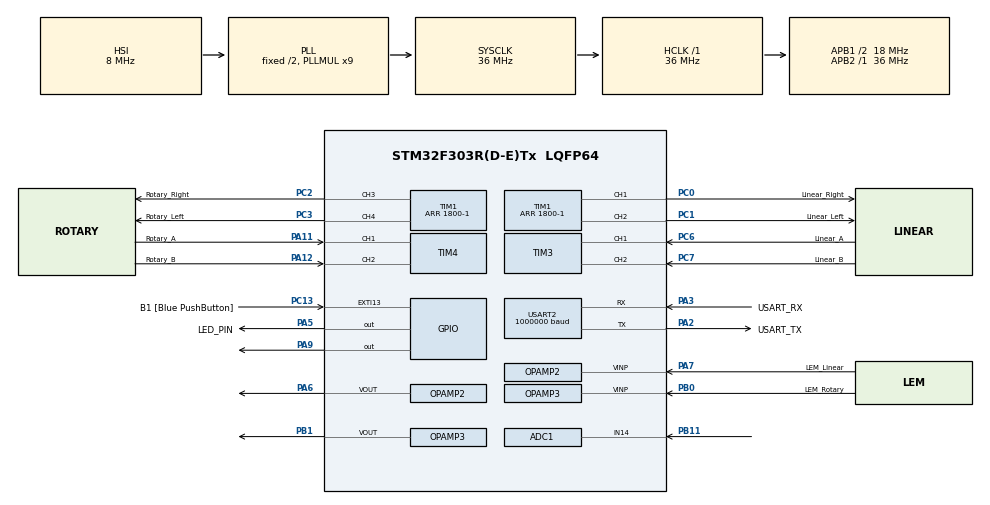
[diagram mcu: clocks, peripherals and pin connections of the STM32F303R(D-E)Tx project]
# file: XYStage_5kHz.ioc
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ADC1.Channel-6\#ChannelRegularConversion=ADC_CHANNEL_14
ADC1.ContinuousConvMode=ENABLE
ADC1.NbrOfConversionFlag=1
ADC1.Offset-6\#ChannelRegularConversion=0
ADC1.OffsetNumber-6\#ChannelRegularConversion=ADC_OFFSET_NONE
ADC1.Rank-6\#ChannelRegularConversion=1
ADC1.SamplingTime-6\#ChannelRegularConversion=ADC_SAMPLETIME_1CYCLE_5
ADC1.master=1
ADC2.Channel-0\#ChannelRegularConversion=ADC_CHANNEL_3
ADC2.ContinuousConvMode=DISABLE
ADC2.ExternalTrigConv=ADC_EXTERNALTRIGCONV_T1_TRGO
ADC2.NbrOfConversionFlag=1
ADC2.Offset-0\#ChannelRegularConversion=0
ADC2.OffsetNumber-0\#ChannelRegularConversion=ADC_OFFSET_NONE
ADC2.Rank-0\#ChannelRegularConversion=1
ADC2.SamplingTime-0\#ChannelRegularConversion=ADC_SAMPLETIME_61CYCLES_5
ADC2.SamplingTimeOPAMP-0\#ChannelRegularConversion=ADC_SAMPLETIME_61CYCLES_5
ADC3.Channel-0\#ChannelRegularConversion=ADC_CHANNEL_1
ADC3.ContinuousConvMode=DISABLE
ADC3.ExternalTrigConv=ADC_EXTERNALTRIGCONV_T1_TRGO
ADC3.NbrOfConversion=1
ADC3.NbrOfConversionFlag=1
ADC3.Offset-0\#ChannelRegularConversion=0
ADC3.OffsetNumber-0\#ChannelRegularConversion=ADC_OFFSET_NONE
ADC3.Rank-0\#ChannelRegularConversion=1
ADC3.SamplingTime-0\#ChannelRegularConversion=ADC_SAMPLETIME_19CYCLES_5
ADC3.master=1
Dma.Request0=USART2_RX
Dma.Request1=USART2_TX
Dma.USART2_RX.0.Direction=DMA_PERIPH_TO_MEMORY
Dma.USART2_RX.0.Instance=DMA1_Channel6
Dma.USART2_RX.0.MemDataAlignment=DMA_MDATAALIGN_BYTE
Dma.USART2_RX.0.MemInc=DMA_MINC_ENABLE
Dma.USART2_RX.0.Mode=DMA_NORMAL
Dma.USART2_RX.0.PeriphDataAlignment=DMA_PDATAALIGN_BYTE
Dma.USART2_RX.0.PeriphInc=DMA_PINC_DISABLE
Dma.USART2_RX.0.Priority=DMA_PRIORITY_VERY_HIGH
Dma.USART2_TX.1.Direction=DMA_MEMORY_TO_PERIPH
Dma.USART2_TX.1.Instance=DMA1_Channel7
Dma.USART2_TX.1.MemDataAlignment=DMA_MDATAALIGN_BYTE
Dma.USART2_TX.1.MemInc=DMA_MINC_ENABLE
Dma.USART2_TX.1.Mode=DMA_NORMAL
Dma.USART2_TX.1.PeriphDataAlignment=DMA_PDATAALIGN_BYTE
Dma.USART2_TX.1.PeriphInc=DMA_PINC_DISABLE
Dma.USART2_TX.1.Priority=DMA_PRIORITY_VERY_HIGH
Mcu.Family=STM32F3
Mcu.Name=STM32F303R(D-E)Tx
Mcu.Package=LQFP64
NVIC.ADC3_IRQn=true\:0\:0\:false\:false\:true\:true\:true\:true
NVIC.DMA1_Channel6_IRQn=true\:0\:0\:false\:false\:true\:false\:true\:true
NVIC.DMA1_Channel7_IRQn=true\:0\:0\:false\:false\:true\:false\:true\:true
NVIC.PriorityGroup=NVIC_PRIORITYGROUP_0
NVIC.USART2_IRQn=true\:0\:0\:false\:false\:true\:true\:true\:true
PA11.GPIO_Label=Rotary_A
PA11.Signal=S_TIM4_CH1
PA12.GPIO_Label=Rotary_B
PA12.Signal=S_TIM4_CH2
PA13.GPIO_Label=TMS
PA13.Mode=Serial_Wire
PA13.Signal=SYS_JTMS-SWDIO
PA14.GPIO_Label=TCK
PA14.Mode=Serial_Wire
PA14.Signal=SYS_JTCK-SWCLK
PA2.GPIO_Label=USART_TX
PA2.GPIO_Mode=GPIO_MODE_AF_PP
PA2.GPIO_PuPd=GPIO_NOPULL
PA2.GPIO_Speed=GPIO_SPEED_FREQ_LOW
PA2.Mode=Asynchronous
PA2.Signal=USART2_TX
PA3.GPIO_Label=USART_RX
PA3.GPIO_Mode=GPIO_MODE_AF_PP
PA3.GPIO_PuPd=GPIO_NOPULL
PA3.GPIO_Speed=GPIO_SPEED_FREQ_LOW
PA3.Mode=Asynchronous
PA3.Signal=USART2_RX
PA5.GPIO_Label=LED_PIN
PA5.Signal=GPIO_Output
PA6.Signal=SharedAnalog_PA6
PA7.GPIO_Label=LEM_Linear
PA7.Mode=Follower
PA7.Signal=OPAMP2_VINP
PA9.Signal=GPIO_Output
PB0.GPIO_Label=LEM_Rotary
PB0.Mode=Follower
PB0.Signal=OPAMP3_VINP
PB1.Signal=SharedAnalog_PB1
PB11.Mode=IN14-Single-Ended
PB11.Signal=ADC1_IN14
PB3.GPIO_Label=SWO
PB3.Signal=SYS_JTDO-TRACESWO
PC0.GPIO_Label=Linear_Right
PC0.Signal=S_TIM1_CH1
PC1.GPIO_Label=Linear_Left
PC1.Signal=S_TIM1_CH2
PC12.Signal=UART5_TX
PC13.GPIO_Label=B1 [Blue PushButton]
PC13.GPIO_ModeDefaultEXTI=GPIO_MODE_IT_FALLING
PC13.Signal=GPXTI13
PC14-OSC32_IN.Mode=LSE-External-Oscillator
PC14-OSC32_IN.Signal=RCC_OSC32_IN
PC15-OSC32_OUT.Mode=LSE-External-Oscillator
PC15-OSC32_OUT.Signal=RCC_OSC32_OUT
PC2.GPIO_Label=Rotary_Right
PC2.Signal=S_TIM1_CH3
PC3.GPIO_Label=Rotary_Left
PC3.Signal=S_TIM1_CH4
PC6.GPIO_Label=Linear_A
PC6.Signal=S_TIM3_CH1
PC7.GPIO_Label=Linear_B
PC7.Signal=S_TIM3_CH2
PD2.Signal=UART5_RX
PF0-OSC_IN.Mode=HSE-External-Clock-Source
PF0-OSC_IN.Signal=RCC_OSC_IN
PF1-OSC_OUT.Signal=RCC_OSC_OUT
ProjectManager.HeapSize=0x200
ProjectManager.StackSize=0x400
ProjectManager.TargetToolchain=STM32CubeIDE
RCC.AHBFreq_Value=36000000
RCC.APB1CLKDivider=RCC_HCLK_DIV2
RCC.APB1Freq_Value=18000000
RCC.APB1TimFreq_Value=36000000
RCC.APB2Freq_Value=36000000
RCC.APB2TimFreq_Value=36000000
RCC.CortexFreq_Value=36000000
RCC.HCLKFreq_Value=36000000
RCC.HSE_VALUE=8000000
RCC.HSI_VALUE=8000000
RCC.PLLM=8
RCC.PLLMUL=RCC_PLL_MUL9
RCC.PLLN=336
RCC.PLLP=RCC_PLLP_DIV4
RCC.PLLQ=7
RCC.RCC_PLLsource_Clock_Source_FROM_HSE=RCC_HSE_PREDIV_DIV2
RCC.SYSCLKFreq_VALUE=36000000
RCC.SYSCLKSourceVirtual=RCC_SYSCLKSOURCE_PLLCLK
RCC.USBFreq_Value=36000000
SH.S_TIM1_CH1.0=TIM1_CH1,PWM Generation1 CH1
SH.S_TIM1_CH2.0=TIM1_CH2,PWM Generation2 CH2
SH.S_TIM1_CH3.0=TIM1_CH3,PWM Generation3 CH3
SH.S_TIM1_CH4.0=TIM1_CH4,PWM Generation4 CH4
SH.S_TIM3_CH1.0=TIM3_CH1,Encoder_Interface
SH.S_TIM3_CH2.0=TIM3_CH2,Encoder_Interface
SH.S_TIM4_CH1.0=TIM4_CH1,Encoder_Interface
SH.S_TIM4_CH2.0=TIM4_CH2,Encoder_Interface
SH.SharedAnalog_PA6.0=ADC2_IN3
SH.SharedAnalog_PA6.1=OPAMP2_VOUT,Follower
SH.SharedAnalog_PB1.0=ADC3_IN1
SH.SharedAnalog_PB1.1=OPAMP3_VOUT,Follower
TIM1.Channel-PWM\ Generation1\ CH1=TIM_CHANNEL_1
TIM1.Channel-PWM\ Generation2\ CH2=TIM_CHANNEL_2
TIM1.Channel-PWM\ Generation3\ CH3=TIM_CHANNEL_3
TIM1.Channel-PWM\ Generation4\ CH4=TIM_CHANNEL_4
TIM1.CounterMode=TIM_COUNTERMODE_CENTERALIGNED1
TIM1.Period=1800-1
TIM1.RepetitionCounter=1
TIM1.TIM_MasterOutputTrigger=TIM_TRGO_UPDATE
TIM3.EncoderMode=TIM_ENCODERMODE_TI12
TIM3.IC1Polarity=TIM_ICPOLARITY_RISING
TIM3.IC2Polarity=TIM_ICPOLARITY_FALLING
TIM4.EncoderMode=TIM_ENCODERMODE_TI12
USART2.BaudRate=1000000
USART2.VirtualMode-Asynchronous=VM_ASYNC
VP_ADC2_OPAMP_OUT2.Mode=IN3-OPAMP2-Single-Ended
VP_ADC3_OPAMP_OUT3.Mode=IN1-OPAMP3-Single-Ended
VP_TIM1_VS_ClockSourceINT.Mode=Internal
board=NUCLEO-F303RE

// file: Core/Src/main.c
/* USER CODE BEGIN Header */
/**
 ******************************************************************************
 * @file           : main.c
 * @brief          : Main program body
 ******************************************************************************
 * @attention
 *
 * Copyright (c) 2024 STMicroelectronics.
 * All rights reserved.
 *
 * This software is licensed under terms that can be found in the LICENSE file
 * in the root directory of this software component.
 * If no LICENSE file comes with this software, it is provided AS-IS.
 *
 ******************************************************************************
 */
/* USER CODE END Header */
#include "main.h"

/* USER CODE BEGIN Includes */
#include "string.h"
#include "stdio.h"
#include "math.h"

/* USER CODE END Includes */

/* USER CODE BEGIN PTD */

typedef struct {
	const float Mass;
	const float Damping;
	const float SpringConstant;
	const float EncoderGain;
	const uint16_t EncoderOffset;
	volatile float SpringForce[65];

} MechanicalPlantTypeDef;

typedef struct {
	volatile uint32_t Counter;
	volatile float Position;
	volatile float PositionHistory[24];
	volatile float Velocity;
	volatile float springForce;
} MechanicalMeasurementTypeDef;

typedef struct {
	volatile uint8_t Active;
	volatile uint8_t ControlMode;
	volatile float DesiredValue;
	volatile float Error[3];
	volatile float Saturation;
	volatile float ControlEffort[3];
	volatile float ControlEffortZP[2];
	volatile float DesiredValueZP[3];
	volatile float DesiredValueZP_P1;
	volatile float FFControlEffort;
	volatile uint8_t Updated;
	volatile float SoftTouchThreshold;
	volatile uint8_t SoftTouch;
	volatile float posSetX;
	volatile float posSetY;
	volatile float startPos;
	volatile uint32_t velCounter;
} MechanicalControllerTypeDef;

////////////////////////////////////////////////////////////////////////////////
/* CC: Current Control -------------------------------------------------------*/
/* LEM is soldered to use three primary turns resulting in 0.625 V / 2 A -----*/
////////////////////////////////////////////////////////////////////////////////
typedef struct {
	const float Resistance;
	const float Inductance;
	const float LEMGain;
	volatile float LEMOffset;
} ElectricalPlantTypeDef;

typedef struct {
	volatile uint32_t Counter;
	volatile float Current;
	volatile float CurrentHistory[24];
} ElectricalMeasurementTypeDef;

typedef struct {
//	const float IndSaturation;

	volatile uint8_t ControlMode;
	volatile float Saturation;
	volatile float DesiredValue;
	volatile float Error[2];
	volatile float ControlEffort[2];
	volatile float ExtForceSaturation;
} ElectricalControllerTypeDef;

typedef struct {
	volatile uint8_t ControllerActive;
	MechanicalPlantTypeDef MP;
	MechanicalMeasurementTypeDef MM;
	MechanicalMeasurementTypeDef MMLog;
	MechanicalControllerTypeDef MC;
	MechanicalControllerTypeDef MCLog;
	ElectricalPlantTypeDef EP;
	ElectricalMeasurementTypeDef EM;
	ElectricalMeasurementTypeDef EMLog;
	ElectricalControllerTypeDef EC;
	ElectricalControllerTypeDef ECLog;

} ActuatorTypeDef;

/* USER CODE END PTD */

/* USER CODE BEGIN PD */
#define IDLE_COMMAND						0
#define	HOME_COMMAND						1
#define	START_COMMAND						2
#define STOP_COMMAND						3
#define MEASUREMENT_COMMAND					4
#define CURRENT_OFFSET_COMMAND				5
#define SPRING_CHARACTERIZATION_COMMAND		6
#define IDENTIFICATION_COMMAND				7
#define FORCE_CONSTANT_CHARACTERIZATION		8

#define LINEAR_VOLTAGE_STEP_COMMAND			9
#define LINEAR_CURRENT_STEP_COMMAND			10
#define LINEAR_POSITION_STEP_COMMAND		     11
#define LINEAR_POSITION_RAMP_COMMAND			 12

#define ROTARY_VOLTAGE_STEP_COMMAND			13
#define ROTARY_CURRENT_STEP_COMMAND			14
#define ROTARY_POSITION_STEP_COMMAND		     15
#define ROTARY_RAMP_COMMAND					16

#define STAIR_COMMAND						17
#define CIRCLE_COMMAND						18
#define SQUARE_COMMAND					    19
#define TRIANGLE_COMMAND				    20
#define SINX_COMMAND                    21
#define SINESTEP_COMMAND                SINX_COMMAND  // Legacy internal alias
#define PRINT_COMMAND						22
#define PETAL_COMMAND						23
#define EPITROCHOID_COMMAND					24
#define CURRENT_PRINT_COMMAND				25  // Temporary X/Y current log output
#define SINY_COMMAND                    26
#define LISSAJOUS12_COMMAND             27  // Serial command: LIS1 (frequency ratio 1:2)
#define LISSAJOUS23_COMMAND             28  // Serial command: LIS2 (frequency ratio 2:3)

////////////////////////////////////////////////////////////////////////////////
/* Control Mode --------------------------------------------------------------*/
////////////////////////////////////////////////////////////////////////////////
#define VOLTAGE_CONTROL						0
#define	CURRENT_CONTROL						1
#define	FORCE_CONTROL						2
#define ACCELERATION_CONTROL				3
#define VELOCITY_CONTROL					4
#define POSITION_CONTROL					5
#define MEASUREMENT_ONLY					6
#define DONT_CHANGE_IT						7

#define UART_RX_BUFFER_SIZE 				256
#define UART_TX_BUFFER_SIZE 				2048

#define LOG_IDLE 							0
#define LOG_NEW_DATA_READY					1
#define LOG_OVERRUN							2
#define Frequency							24000
#define PWMARR								7200.0f
#define PPR									1000.0f
#define BusVoltage							24.0f
#define V								0
#define U								1
#define Rotary_Encoder_Offset				32768.0f

#define RAMP_STROKE							20.000f // mm
#define Linear_Ramp_Vel						5.000f // mm/s
#define Linear_Ramp_Duration				RAMP_STROKE/Linear_Ramp_Vel	 //
#define LINEAR_RAMP_CYCLES					1

#define Rotary_Ramp_Vel						150.000f // deg/s
#define Rotary_Ramp_Duration				180.000f/Rotary_Ramp_Vel	 //
#define KNOB_TEST_CYCLES					1
#define Transformation                      -0.70710678118f //cos(M_PI_4)
#define DesiredTransformation                0.70710678118f //cos(M_PI_4)

#define SamplingFreq						5000.0f
#define PrintFreq							500.0f

//#define SINESTEP_DURATION_SAMPLES  ((uint32_t)(2.0f * SamplingFreq))
//#define SINESTEP_SETTLE_SAMPLES    2500U  // 0.5 seconds at 5 kHz

// ILC configuration
#define ILC_BETA                  0.5f  // Used by model-inverse ILC only.
#define ILC_USE_MODEL_INVERSE     0U    // 1: model inverse; 0: PD ILC, for both axes.
#define ILC_MAX_CORRECTION_MM     2.0f
#define MODEL_INVERSE_Q_FC_HZ     50.0f
#define PDILC_Q_FC_HZ             50.0f

// Independent PD-ILC gains for each Cartesian axis. Tune X and Y separately.
// The initial values preserve the previous gains; update them independently as needed.
#define PDILC_KP_X                0.9f
#define PDILC_KD_X               10.0f
#define PDILC_KP_Y                0.9f
#define PDILC_KD_Y               10.0f

#define ILC_TRIAL_SAMPLES         5000U
#define ILC_RMS_START_SAMPLE      1000U  // 1-based sample number; steady RMS includes samples 1000 through 5000.

// Temporary current logging: retain every 10th ILC sample (nominally 500 Hz).
#define CURRENT_LOG_DECIMATION    10U
#define CURRENT_LOG_SAMPLES       ((ILC_TRIAL_SAMPLES + CURRENT_LOG_DECIMATION - 1U) / CURRENT_LOG_DECIMATION)
#define SINESTEP_DURATION_SAMPLES ILC_TRIAL_SAMPLES
#define SINESTEP_SETTLE_SAMPLES    2500U

#define SINESTEP_TOTAL_SAMPLES \
    (SINESTEP_DURATION_SAMPLES + SINESTEP_SETTLE_SAMPLES)

// CIRCLE ILC: ramp to the circle start point, learn over one repeatable
// 1-second circular segment, then hold at that same point for settling.
#define CIRCLE_RAMP_DURATION_S   0.25f
#define CIRCLE_RAMP_SAMPLES      ((uint32_t)(CIRCLE_RAMP_DURATION_S * SamplingFreq))
#define CIRCLE_TRIAL_END_SAMPLE  (CIRCLE_RAMP_SAMPLES + ILC_TRIAL_SAMPLES)
#define CIRCLE_TOTAL_SAMPLES     (CIRCLE_TRIAL_END_SAMPLE + SINESTEP_SETTLE_SAMPLES)

// PETAL ILC uses the same repeatable structure: unlearned ramp, 1-second
// learning window (5000 samples, four complete 0.25-second petal periods),
// then a hold at the petal starting point while feedback remains active.
#define PETAL_RAMP_DURATION_S   0.25f
#define PETAL_RAMP_SAMPLES      ((uint32_t)(PETAL_RAMP_DURATION_S * SamplingFreq))
#define PETAL_TRIAL_END_SAMPLE  (PETAL_RAMP_SAMPLES + ILC_TRIAL_SAMPLES)
#define PETAL_TOTAL_SAMPLES     (PETAL_TRIAL_END_SAMPLE + SINESTEP_SETTLE_SAMPLES)

// Lissajous ILC uses the same 0.25 s approach, 1 s learned path, and 0.5 s hold.
// Both axes use zero phase at the selected base time; the Y phase offset is 0 rad.
#define LISSAJOUS_RAMP_DURATION_S  0.25f
#define LISSAJOUS_RAMP_SAMPLES     ((uint32_t)(LISSAJOUS_RAMP_DURATION_S * SamplingFreq))
#define LISSAJOUS_TRIAL_END_SAMPLE (LISSAJOUS_RAMP_SAMPLES + ILC_TRIAL_SAMPLES)
#define LISSAJOUS_TOTAL_SAMPLES    (LISSAJOUS_TRIAL_END_SAMPLE + SINESTEP_SETTLE_SAMPLES)
#define LISSAJOUS_A_X_MM           2.0f
#define LISSAJOUS_A_Y_MM           2.0f
#define LISSAJOUS_PHASE_Y_RAD      0.0f
#define LISSAJOUS12_FX_HZ          5.0f
#define LISSAJOUS12_FY_HZ          10.0f
#define LISSAJOUS23_FX_HZ          4.0f
#define LISSAJOUS23_FY_HZ          6.0f

/* USER CODE END PD */

ADC_HandleTypeDef hadc1;
ADC_HandleTypeDef hadc2;
ADC_HandleTypeDef hadc3;

OPAMP_HandleTypeDef hopamp2;
OPAMP_HandleTypeDef hopamp3;

TIM_HandleTypeDef htim1;
TIM_HandleTypeDef htim3;
TIM_HandleTypeDef htim4;

UART_HandleTypeDef huart2;
DMA_HandleTypeDef hdma_usart2_rx;
DMA_HandleTypeDef hdma_usart2_tx;

/* USER CODE BEGIN PV */
/* UART ----------------------------------------------------------------------*/
////////////////////////////////////////////////////////////////////////////////
__attribute__ ((section(".buffers"), used))
char UARTTXBuffer[UART_TX_BUFFER_SIZE];
uint16_t UARTTXLen;
uint8_t UARTRXBuffer[UART_RX_BUFFER_SIZE];

volatile uint8_t ActiveCommand;
volatile uint8_t HalfTrigger;
volatile uint8_t ControlLog;
volatile uint16_t SerialOverrun;
volatile uint16_t LogOverrun;
volatile uint8_t DataLogStatus;
volatile float TEMP;

volatile uint32_t LogCounter = 0;
volatile uint32_t PrintNumbers ;

// The correction profile is shared between commands to conserve SRAM. Keep
// it when repeating the same task, but clear it when switching trajectory type.
static uint8_t ILC_ActiveProfileCommand = IDLE_COMMAND;

//float CURRENTLOG_V[2000];
//float CURRENTLOG_U[2000];
//float PosLog_X[2000];
//float PosLog_Y[2000];
//float PosLog_U[2000];
//float PosLog_V[2000];

// Full-trial ILC buffers for both axes. Values are stored in micrometres
// (int16_t) to limit SRAM use; the ILC calculations remain in float.
static volatile int16_t ilcErrorX_um[ILC_TRIAL_SAMPLES] = {0};
static volatile int16_t ilcCorrectionX_um[ILC_TRIAL_SAMPLES] = {0};
static volatile int16_t ilcErrorY_um[ILC_TRIAL_SAMPLES] = {0};
static volatile int16_t ilcCorrectionY_um[ILC_TRIAL_SAMPLES] = {0};

// Temporary current capture in milliamps; downsampled to reduce SRAM use.
static volatile int16_t currentLogX_mA[CURRENT_LOG_SAMPLES] = {0};
static volatile int16_t currentLogY_mA[CURRENT_LOG_SAMPLES] = {0};

//uint32_t LogC[1000];
//float EC_ConEffX_LOG[2000] ;
//float EC_ConEffY_LOG[2000] ;

//float MC_ConEffX_LOG[1000];
//float MC_ConEffY_LOG[1000];
//float EC_ConEffX_LOG[1000];
//float EC_ConEffY_LOG[1000];
//float MC_ErrX_LOG[1000];
//float MC_ErrY_LOG[1000];
//float EC_ErrX_LOG[1000];
//float EC_ErrY_LOG[1000];
//volatile float x_cos[2000];
//volatile float y_sin[2000];

volatile uint32_t PrintNumbers = 2000;
const float R_circle =  2.0f;                 //radius of circle
const float freq_circle = 10.0f * M_PI * 2.0f; // angular frequency (10 Hz)

// Calculated at CIRC startup; the ISR uses this same point for ramp end and hold.
static volatile float circleStartX_mm = 0.0f;
static volatile float circleStartY_mm = 0.0f;

// Calculated at PETL startup; the ISR uses this same point for ramp end and hold.
static volatile float petalStartX_mm = 0.0f;
static volatile float petalStartY_mm = 0.0f;

// Calculated at LISSAJOUS startup and reused for the approach ramp and settling hold.
static volatile float lissajousStartX_mm = 0.0f;
static volatile float lissajousStartY_mm = 0.0f;

const float petal_freq = 2.0f * (2.0f * M_PI);   // = 4*pi rad/s (2 Hz)
const float petal_dim =  3.0f;                 //radius of circle
const float petal_num =  5.0f;
const float petal_turn = 1.0f;

const float epi_R     = 5.0f;      // R (mm)
const float epi_r     = 2.0f;      // r (mm)
const float epi_n     = 6.0f;      // n loops
const float epi_T     = 4.0f;      // total time (s)
const float epi_turns = 1.0f;      // number of base revolutions
const float epi_freq  = 2.0f * M_PI / epi_T;  // ω₀ = 2π/T = π/2 rad/s

const float amplitude_square = 5.0f;  		 // half side length
const float freq_square   = 0.5f;     		 //  Hz

const float amplitude_triangle = 5.0f;  // distance from center to vertex in Y
const float freq_triangle  = 0.5f; // convert F (rad/s) to Hz

volatile uint32_t PrintCounter = 0;
volatile uint32_t STPOS = 0;
volatile float PosU;
volatile float PosV;
volatile uint32_t timeS = 0;
volatile uint32_t timeE = 0;
volatile uint32_t timeCode = 0;
// V Actuator
ActuatorTypeDef YActuator = {

.MP = { .Mass = 0.387, .Damping = 12, .SpringConstant = 272.4,
		.SpringForce = { 0.9131, 0.9650, 0.9701, 0.9748, 1.0031, 1.0222, 1.0343,
				1.0447, 1.0545, 1.0877, 1.1104, 1.1264, 1.1361, 1.1590, 1.1793,
				1.2015, 1.2047, 1.2270, 1.2300, 1.2724, 1.2959, 1.2889, 1.3176,
				1.3214, 1.3534, 1.3804, 1.3771, 1.3929, 1.4204, 1.4529, 1.4629,
				1.4766, 1.4763, 1.5222, 1.5490, 1.5514, 1.5599, 1.5828, 1.6353,
				1.6720, 1.6408, 1.6679, 1.6981, 1.7413, 1.8062, 1.7907, 1.8090,
				1.7915, 1.8280, 1.8629, 1.9222, 1.9268, 1.9679, 2.0286 },
		.EncoderGain = 2.0f / 1024.0f, .EncoderOffset = 28385 }, .EP = {
		.Resistance = 7.3, .Inductance = 0.0075, .LEMGain = 8.0f }, .EC = {
		.ExtForceSaturation = 3.0f } };

ActuatorTypeDef XActuator = {

.MP = { .Mass = 0.387, .Damping = 12, .SpringConstant = 272.4, .EncoderGain =
		2.0f / 1024.0f, .EncoderOffset = 32776 }, .EP = { .Resistance = 7.3,
		.Inductance = 0.0075, .LEMGain = 8.0f } };

/* USER CODE END PV */

void SystemClock_Config(void);
static void MX_GPIO_Init(void);
static void MX_DMA_Init(void);
static void MX_OPAMP2_Init(void);
static void MX_OPAMP3_Init(void);
static void MX_TIM1_Init(void);
static void MX_TIM3_Init(void);
static void MX_ADC1_Init(void);
static void MX_ADC2_Init(void);
static void MX_ADC3_Init(void);
static void MX_TIM4_Init(void);
static void MX_USART2_UART_Init(void);
/* USER CODE BEGIN PFP */

volatile float ForceConstant(float Position);
volatile float BridgeDriver(uint8_t Axis, float ControlEffort);
void StartActuators();
void SetControlParameters(uint8_t Active, uint8_t MControlMode,
		float MDesiredValueX, float MDesiredValueY, uint8_t EControlMode,
		float EDesiredValueU, float EDesiredValueV, uint8_t Log);
volatile uint8_t ProcessSerialCommand(uint8_t *SerialCommand);
void StopActuators();
void MMeasurement();
void EMeasurement();
void LogData();
void ReInitMechanicalController();

// ILC conversion helpers, performance metrics, and update laws.
static int16_t ILC_MmToMicrometres(float valueMm);
static float ILC_MicrometresToMm(int16_t valueUm);
static void ILC_ResetCorrections(void);
static void PDILC_Update(void);
static void PDILC_UpdateAxis(
    volatile int16_t *errorUm, volatile int16_t *correctionUm,
    float kp, float kd);
static void ModelInverseILC_Update(void);
static void ModelInverseILC_UpdateAxis(
    volatile int16_t *errorUm, volatile int16_t *correctionUm,
    float b1Plant, float b2Plant, float a1Plant, float a2Plant, float a3Plant);
static float ILC_CalculateRMS(const volatile int16_t *errorUm);
static float ILC_CalculateRMS_SteadyState(const volatile int16_t *errorUm);
static float ILC_MaxCorrection(const volatile int16_t *correctionUm);

/* USER CODE END PFP */

int main(void)
{

  /* MCU Configuration--------------------------------------------------------*/

  /* Reset of all peripherals, Initializes the Flash interface and the Systick. */
  HAL_Init();

  /* Configure the system clock */
  SystemClock_Config();

  /* Initialize all configured peripherals */
  MX_GPIO_Init();
  MX_DMA_Init();
  MX_OPAMP2_Init();
  MX_OPAMP3_Init();
  MX_TIM1_Init();
  MX_TIM3_Init();
  MX_ADC1_Init();
  MX_ADC2_Init();
  MX_ADC3_Init();
  MX_TIM4_Init();
  MX_USART2_UART_Init();
  /* USER CODE BEGIN 2 */
	HAL_UARTEx_ReceiveToIdle_IT(&huart2, UARTRXBuffer, UART_RX_BUFFER_SIZE);

	HAL_TIM_Encoder_Start(&htim3, TIM_CHANNEL_ALL);
	HAL_TIM_Encoder_Start(&htim4, TIM_CHANNEL_ALL);

////  HOME
//	__HAL_TIM_SET_COUNTER(&htim4, XActuator.MP.EncoderOffset);
//	__HAL_TIM_SET_COUNTER(&htim3, YActuator.MP.EncoderOffset);

	HAL_OPAMP_SelfCalibrate(&hopamp2);
	HAL_OPAMP_Start(&hopamp2);

	HAL_OPAMP_SelfCalibrate(&hopamp3);
	HAL_OPAMP_Start(&hopamp3);

	HAL_ADCEx_Calibration_Start(&hadc2, ADC_SINGLE_ENDED);
	HAL_ADCEx_Calibration_Start(&hadc3, ADC_SINGLE_ENDED);

  /* USER CODE END 2 */

  /* Infinite loop */
  /* USER CODE BEGIN WHILE */
	while (1) {

//		XActuator.MM.Position = ((float) XActuator.MP.EncoderOffset
//				- __HAL_TIM_GET_COUNTER(&htim4)) * XActuator.MP.EncoderGain + 8;
//
//		YActuator.MM.Position = -((float) YActuator.MP.EncoderOffset
//				- __HAL_TIM_GET_COUNTER(&htim3)) * YActuator.MP.EncoderGain;
//
////		PosU = XActuator.MM.Position * -1.0f * Transformation
////				+ YActuator.MM.Position * Transformation;
////
////		PosV = XActuator.MM.Position * Transformation
////				+ YActuator.MM.Position * Transformation;
//
//
//		PosU = XActuator.MM.Position * (float) DesiredTransformation
//				+ YActuator.MM.Position * (float) DesiredTransformation;
//
//		PosV = XActuator.MM.Position * -1.0f * (float) DesiredTransformation
//				+ YActuator.MM.Position * (float) DesiredTransformation;
//
//
//
//		YActuator.MC.Error[0] = 10.0f * DesiredTransformation - PosV;
//		XActuator.MC.Error[0] = 10.0f * Transformation - PosU;
//
//		YActuator.EM.Current = -((float) HAL_ADC_GetValue(&hadc1)
//				- YActuator.EP.LEMOffset) / 4096.0f * 3.3f
//				* YActuator.EP.LEMGain;
//
//		XActuator.EM.Current = (HAL_ADC_GetValue(&hadc2)
//				- XActuator.EP.LEMOffset) / 4096.0f * 3.3
//				* XActuator.EP.LEMGain;

		switch (ActiveCommand) {

		case HOME_COMMAND:

			if (LogCounter == 0) {
				HAL_UART_DMAStop(&huart2);
				UARTTXLen = sprintf((char*) UARTTXBuffer, "Home Command\n");
				HAL_UART_Transmit(&huart2, (uint8_t*) UARTTXBuffer, UARTTXLen, 100);

				StartActuators();
				//HAL_Delay(500);
				__HAL_TIM_SET_COUNTER(&htim3, YActuator.MP.EncoderOffset);
				__HAL_TIM_SET_COUNTER(&htim4, XActuator.MP.EncoderOffset);

				STPOS = 1;

			} else if (LogCounter <= 0.5f * SamplingFreq) {
				// 8.0f is home target
				float position_now  = ( 8.0f / (0.5f * SamplingFreq) ) * (LogCounter);
				SetControlParameters(1, POSITION_CONTROL,
						8.0f-position_now, 0,
									DONT_CHANGE_IT, 0, 0, 0);

			} else if (LogCounter > 1.0f * SamplingFreq) {

				SetControlParameters(0, MEASUREMENT_ONLY, 0, 0,
				MEASUREMENT_ONLY, 0, 0, 0);
//				HAL_Delay(100);
				StopActuators();
				ActiveCommand = IDLE_COMMAND;
				STPOS = 0;
				UARTTXLen = sprintf((char*) UARTTXBuffer, "Finished\n");
				HAL_UART_Transmit(&huart2, (uint8_t*) UARTTXBuffer, UARTTXLen, 100);

			}

			break;

case PRINT_COMMAND: {

		    HAL_UART_DMAStop(&huart2);

		    // Mark the data block so multiple trials can be pasted into one log file.
		    // The command identifies which reference MATLAB should reconstruct.
		    const char *profileName = "UNKNOWN";
		    float profileRampSeconds = 0.0f;
		    float profileRadius_mm = R_circle;
		    float profileFrequency_Hz = freq_circle / (2.0f * (float)M_PI);
		    float profilePetalNum = 0.0f;
		    float profilePetalTurn = 0.0f;
		    float profileFx_Hz = profileFrequency_Hz;
		    float profileFy_Hz = profileFrequency_Hz;
		    float profilePhaseY_deg = 0.0f;
		    if (ILC_ActiveProfileCommand == SINX_COMMAND) {
		        profileName = "SINX";
		    } else if (ILC_ActiveProfileCommand == SINY_COMMAND) {
		        profileName = "SINY";
		    } else if (ILC_ActiveProfileCommand == CIRCLE_COMMAND) {
		        profileName = "CIRC";
		        profileRampSeconds = CIRCLE_RAMP_DURATION_S;
		    } else if (ILC_ActiveProfileCommand == PETAL_COMMAND) {
		        profileName = "PETAL";
		        profileRampSeconds = PETAL_RAMP_DURATION_S;
		        profileRadius_mm = petal_dim;
		        profileFrequency_Hz = petal_freq / (2.0f * (float)M_PI);
		        profilePetalNum = petal_num;
		        profilePetalTurn = petal_turn;
		        profileFx_Hz = profileFrequency_Hz;
		        profileFy_Hz = profileFrequency_Hz;
		    } else if (ILC_ActiveProfileCommand == LISSAJOUS12_COMMAND) {
		        profileName = "LIS12";
		        profileRampSeconds = LISSAJOUS_RAMP_DURATION_S;
		        profileRadius_mm = LISSAJOUS_A_X_MM;
		        profileFrequency_Hz = LISSAJOUS12_FX_HZ;
		        profileFx_Hz = LISSAJOUS12_FX_HZ;
		        profileFy_Hz = LISSAJOUS12_FY_HZ;
		        profilePhaseY_deg = LISSAJOUS_PHASE_Y_RAD * 180.0f / (float)M_PI;
		    } else if (ILC_ActiveProfileCommand == LISSAJOUS23_COMMAND) {
		        profileName = "LIS23";
		        profileRampSeconds = LISSAJOUS_RAMP_DURATION_S;
		        profileRadius_mm = LISSAJOUS_A_X_MM;
		        profileFrequency_Hz = LISSAJOUS23_FX_HZ;
		        profileFx_Hz = LISSAJOUS23_FX_HZ;
		        profileFy_Hz = LISSAJOUS23_FY_HZ;
		        profilePhaseY_deg = LISSAJOUS_PHASE_Y_RAD * 180.0f / (float)M_PI;
		    }

#if ILC_USE_MODEL_INVERSE
		    // Include the selected ILC method and its active settings in each PRNT block.
		    // This header is printed only on request; it does not alter real-time control.
		    UARTTXLen = snprintf(
		        (char*)UARTTXBuffer,
		        UART_TX_BUFFER_SIZE - 1U,
		        "DATA_BEGIN,ILC=MI,beta=%.6f,fc_Hz=%.6f,command=%s,samples=%u,Fs_Hz=%.0f,R_mm=%.6f,freq_Hz=%.6f,ramp_s=%.6f,petal_num=%.6f,petal_turn=%.6f,fx_Hz=%.6f,fy_Hz=%.6f,phase_deg=%.6f\r\n",
		        (double)ILC_BETA,
		        (double)MODEL_INVERSE_Q_FC_HZ,
		        profileName,
		        (unsigned int)ILC_TRIAL_SAMPLES,
		        (double)SamplingFreq,
		        (double)profileRadius_mm,
		        (double)profileFrequency_Hz,
		        (double)profileRampSeconds,
		        (double)profilePetalNum,
		        (double)profilePetalTurn,
		        (double)profileFx_Hz,
		        (double)profileFy_Hz,
		        (double)profilePhaseY_deg);
#else
		    UARTTXLen = snprintf(
		        (char*)UARTTXBuffer,
		        UART_TX_BUFFER_SIZE - 1U,
		        "DATA_BEGIN,ILC=PD,KPX=%.6f,KDX=%.6f,KPY=%.6f,KDY=%.6f,fc_Hz=%.6f,command=%s,samples=%u,Fs_Hz=%.0f,R_mm=%.6f,freq_Hz=%.6f,ramp_s=%.6f,petal_num=%.6f,petal_turn=%.6f,fx_Hz=%.6f,fy_Hz=%.6f,phase_deg=%.6f\r\n",
		        (double)PDILC_KP_X,
		        (double)PDILC_KD_X,
		        (double)PDILC_KP_Y,
		        (double)PDILC_KD_Y,
		        (double)PDILC_Q_FC_HZ,
		        profileName,
		        (unsigned int)ILC_TRIAL_SAMPLES,
		        (double)SamplingFreq,
		        (double)profileRadius_mm,
		        (double)profileFrequency_Hz,
		        (double)profileRampSeconds,
		        (double)profilePetalNum,
		        (double)profilePetalTurn,
		        (double)profileFx_Hz,
		        (double)profileFy_Hz,
		        (double)profilePhaseY_deg);
#endif
		    HAL_UART_Transmit(&huart2, (uint8_t*)UARTTXBuffer, UARTTXLen, 100);

		    UARTTXLen = snprintf(
		        (char*)UARTTXBuffer,
		        UART_TX_BUFFER_SIZE - 1U,
		        "sample,errorX_mm,correctionX_next_mm,errorY_mm,correctionY_next_mm\r\n");
		    HAL_UART_Transmit(&huart2, (uint8_t*)UARTTXBuffer, UARTTXLen, 100);

		    // Columns: zero-based sample, X error, next-trial X correction,
		    // Y error, next-trial Y correction. Error is reference minus measured output.
		    for (uint32_t ii = 0U; ii < ILC_TRIAL_SAMPLES; ii++) {

		        UARTTXLen = snprintf(
		            (char*)UARTTXBuffer,
		            UART_TX_BUFFER_SIZE - 1U,
		            "%lu,%.6f,%.6f,%.6f,%.6f\r\n",
		            (unsigned long)ii,
		            (double)ILC_MicrometresToMm(ilcErrorX_um[ii]),
		            (double)ILC_MicrometresToMm(ilcCorrectionX_um[ii]),
		            (double)ILC_MicrometresToMm(ilcErrorY_um[ii]),
		            (double)ILC_MicrometresToMm(ilcCorrectionY_um[ii])
		        );

		        HAL_UART_Transmit(
		            &huart2,
		            (uint8_t*)UARTTXBuffer,
		            UARTTXLen,
		            100
		        );
		    }

		    UARTTXLen = snprintf((char*)UARTTXBuffer,
		                         UART_TX_BUFFER_SIZE - 1U,
		                         "DATA_END,command=%s\r\n", profileName);
		    HAL_UART_Transmit(&huart2, (uint8_t*)UARTTXBuffer, UARTTXLen, 100);

		    ActiveCommand = IDLE_COMMAND;
		    break;
		}

		case CURRENT_PRINT_COMMAND:

		    HAL_UART_DMAStop(&huart2);

		    // Columns: zero-based ILC trial sample index, X current [mA], Y current [mA].
		    UARTTXLen = snprintf(
		        (char*)UARTTXBuffer,
		        UART_TX_BUFFER_SIZE - 1U,
		        "sample,I_X_mA,I_Y_mA\r\n");
		    HAL_UART_Transmit(&huart2, (uint8_t*)UARTTXBuffer, UARTTXLen, 100);

		    for (uint32_t ii = 0U; ii < CURRENT_LOG_SAMPLES; ii++) {
		        UARTTXLen = snprintf(
		            (char*)UARTTXBuffer,
		            UART_TX_BUFFER_SIZE - 1U,
		            "%lu,%d,%d\r\n",
		            (unsigned long)(ii * CURRENT_LOG_DECIMATION),
		            (int)currentLogX_mA[ii],
		            (int)currentLogY_mA[ii]);
		        HAL_UART_Transmit(&huart2, (uint8_t*)UARTTXBuffer, UARTTXLen, 100);
		    }

		    ActiveCommand = IDLE_COMMAND;
		    break;

		case CURRENT_OFFSET_COMMAND:
			HAL_UART_DMAStop(&huart2);
			UARTTXLen = sprintf((char*) UARTTXBuffer,
					"Current Offset Command\n");
			HAL_UART_Transmit(&huart2, (uint8_t*) UARTTXBuffer, UARTTXLen, 100);
			StopActuators();

			float LEMTempOffsetX = 0;
			float LEMTempOffsetY = 0;

			HAL_TIM_Base_Start(&htim1);
			HAL_ADC_Start(&hadc2);
			HAL_ADC_Start(&hadc3);

			LEMTempOffsetY = 0;
			LEMTempOffsetX = 0;

			for (uint32_t i = 0; i < 1000; i++) {
				HAL_ADC_PollForConversion(&hadc3, 1);
				uint16_t ADCTempValueX = HAL_ADC_GetValue(&hadc3);
				LEMTempOffsetX += ADCTempValueX / 1000.0f;

				HAL_ADC_PollForConversion(&hadc2, 1);
				uint16_t ADCTempValueY = HAL_ADC_GetValue(&hadc2);
				LEMTempOffsetY += ADCTempValueY / 1000.0f;
			}
			YActuator.EP.LEMOffset = LEMTempOffsetY;
			XActuator.EP.LEMOffset = LEMTempOffsetX;

			HAL_TIM_Base_Stop(&htim1);
			HAL_ADC_Stop(&hadc2);
			HAL_ADC_Stop(&hadc3);

			//StopActuators();
			UARTTXLen = sprintf((char*) UARTTXBuffer,
					"Finished, LEM Offset: V = %f , U = %f\n",
					YActuator.EP.LEMOffset, XActuator.EP.LEMOffset);

			HAL_UART_Transmit(&huart2, (uint8_t*) UARTTXBuffer, UARTTXLen, 100);
			ActiveCommand = IDLE_COMMAND;
			LogCounter = 0;
			break;

			////////////////////////////////////////////////////////////////////////////////
			/*------------------------- V ACTUATOR COMMANDS -------------------------*/
			////////////////////////////////////////////////////////////////////////////////
		case LINEAR_VOLTAGE_STEP_COMMAND:

			if (LogCounter == 0) {
				HAL_UART_DMAStop(&huart2);
				UARTTXLen = sprintf((char*) UARTTXBuffer,
						"V AXIS VOLTAGE STEP COMMAND\n");
				HAL_UART_Transmit(&huart2, (uint8_t*) UARTTXBuffer, UARTTXLen,
						100);
				StartActuators();

				SetControlParameters(1, MEASUREMENT_ONLY, 0, 0,
				VOLTAGE_CONTROL, 3, 0, 0);

			} else if (LogCounter >= 0.5 * SamplingFreq) {

				SetControlParameters(0, MEASUREMENT_ONLY, 0, 0,
				MEASUREMENT_ONLY, 0, 0, 0);
				StopActuators();
				ActiveCommand = IDLE_COMMAND;

				UARTTXLen = sprintf((char*) UARTTXBuffer, "Finished\n");
				HAL_UART_Transmit(&huart2, (uint8_t*) UARTTXBuffer, UARTTXLen,
						100);
			}
			break;

		case LINEAR_CURRENT_STEP_COMMAND:

			if (LogCounter == 0) {
				HAL_UART_DMAStop(&huart2);
				UARTTXLen = sprintf((char*) UARTTXBuffer,
						"V AXIS CURRENT STEP COMMAND\n");
				HAL_UART_Transmit(&huart2, (uint8_t*) UARTTXBuffer, UARTTXLen,
						100);

				SetControlParameters(1, MEASUREMENT_ONLY, 0, 0,
				CURRENT_CONTROL, 0, 0.25, 0);
				STPOS = 1;
				StartActuators();

			} else if (LogCounter >= 0.5 * SamplingFreq) {

				SetControlParameters(0, MEASUREMENT_ONLY, 0, 0,
				MEASUREMENT_ONLY, 0, 0, 0);
				StopActuators();
				ActiveCommand = IDLE_COMMAND;
				STPOS = 0;
				UARTTXLen = sprintf((char*) UARTTXBuffer, "Finished\n");
				HAL_UART_Transmit(&huart2, (uint8_t*) UARTTXBuffer, UARTTXLen,
						100);
			}
			break;

		case SINX_COMMAND:
		case SINY_COMMAND:

					if (LogCounter == 0 && STPOS == 0) {
                        if (ILC_ActiveProfileCommand != ActiveCommand) {
                            // This baseline keeps one shared correction profile.
                            // Repeating the same command learns from its previous trial;
                            // switching between SINX, SINY, and CIRC starts with zero correction.
                            ILC_ResetCorrections();
                            ILC_ActiveProfileCommand = ActiveCommand;
                        }
						HAL_UART_DMAStop(&huart2);
						UARTTXLen = snprintf((char*)UARTTXBuffer,
                            UART_TX_BUFFER_SIZE - 1U, "COMMAND=%s\r\n",
                            (ActiveCommand == SINX_COMMAND) ? "SINX" : "SINY");
						HAL_UART_Transmit(&huart2, (uint8_t*) UARTTXBuffer, UARTTXLen, 100);
						STPOS = 1; // Guard against printing/restarting while LogCounter is still zero.
						StartActuators();

					} else if (LogCounter <
					           SINESTEP_DURATION_SAMPLES + SINESTEP_SETTLE_SAMPLES) {
////						float omegaT = (float) LogCounter / SamplingFreq * freq_circle;
//						float omegaT = (float) (LogCounter) / SamplingFreq * freq_circle;
//										SetControlParameters(1, POSITION_CONTROL,
//												0, R_circle * sinf(omegaT),
//												DONT_CHANGE_IT, 0, 0, 0);

					} else {

					    SetControlParameters(
					        0,
					        MEASUREMENT_ONLY,
					        0.0f,
					        0.0f,
					        MEASUREMENT_ONLY,
					        0.0f,
					        0.0f,
					        0
					    );

					    StopActuators();

					    // Evaluate the current trial before updating the corrections.
					    float errorRMS_X = ILC_CalculateRMS(ilcErrorX_um);
					    float errorRMS_Y = ILC_CalculateRMS(ilcErrorY_um);
					    float errorRMS_X_SteadyState = ILC_CalculateRMS_SteadyState(ilcErrorX_um);
					    float errorRMS_Y_SteadyState = ILC_CalculateRMS_SteadyState(ilcErrorY_um);

#if ILC_USE_MODEL_INVERSE
					    ModelInverseILC_Update();  // Model-inverse ILC updates X and Y.
#else
					    PDILC_Update();            // PD ILC updates X and Y; no beta multiplier.
#endif
                    ILC_ActiveProfileCommand = ActiveCommand;

					    // These peaks describe the corrections to be used in the next trial.
					    float correctionPeakX = ILC_MaxCorrection(ilcCorrectionX_um);
					    float correctionPeakY = ILC_MaxCorrection(ilcCorrectionY_um);

					    ActiveCommand = IDLE_COMMAND;
					    STPOS = 0;

					    UARTTXLen = snprintf(
					        (char*)UARTTXBuffer,
					        UART_TX_BUFFER_SIZE - 1U,
					        "%s finished. X=%.4f mm, Y=%.4f mm, "
					        "RMS_X_full=%.6f mm, RMS_Y_full=%.6f mm, "
					        "RMS_X_samples_%u_to_%u=%.6f mm, "
					        "RMS_Y_samples_%u_to_%u=%.6f mm, "
					        "correction_peak_X_next=%.5f mm, correction_peak_Y_next=%.5f mm\r\n",
					        (ILC_ActiveProfileCommand == SINX_COMMAND) ? "SINX" : "SINY",
					        XActuator.MM.Position,
					        YActuator.MM.Position,
					        errorRMS_X,
					        errorRMS_Y,
					        (unsigned int)ILC_RMS_START_SAMPLE,
					        (unsigned int)ILC_TRIAL_SAMPLES,
					        errorRMS_X_SteadyState,
					        (unsigned int)ILC_RMS_START_SAMPLE,
					        (unsigned int)ILC_TRIAL_SAMPLES,
					        errorRMS_Y_SteadyState,
					        correctionPeakX,
					        correctionPeakY
					    );

					    HAL_UART_Transmit(
					        &huart2,
					        (uint8_t*)UARTTXBuffer,
					        UARTTXLen,
					        100
					    );
					}
					break;
		case STAIR_COMMAND:

			if (LogCounter == 0) {
				HAL_UART_DMAStop(&huart2);
				UARTTXLen = sprintf((char*) UARTTXBuffer,
						"U AXIS CURRENT STEP COMMAND\n");
				HAL_UART_Transmit(&huart2, (uint8_t*) UARTTXBuffer, UARTTXLen, 100);
				STPOS = 1;
				StartActuators();

			} else if (LogCounter <= 1.0 * SamplingFreq) {
				SetControlParameters(1, MEASUREMENT_ONLY, 0, 0,
				CURRENT_CONTROL, 0, 0, 0);

			}else if (LogCounter <= 3.0 * SamplingFreq) {
				SetControlParameters(1, MEASUREMENT_ONLY, 0, 0,
				CURRENT_CONTROL, 0.25, 0, 0);

			}else if (LogCounter <= 4.0 * SamplingFreq) {
				SetControlParameters(1, MEASUREMENT_ONLY, 0, 0,
				CURRENT_CONTROL, 0.0, 0, 0);

			}else if (LogCounter <= 6.0 * SamplingFreq) {
				SetControlParameters(1, MEASUREMENT_ONLY, 0, 0,
				CURRENT_CONTROL, 0.5, 0, 0);

			}else if (LogCounter <= 7.0 * SamplingFreq) {
				SetControlParameters(1, MEASUREMENT_ONLY, 0, 0,
				CURRENT_CONTROL, 0.0, 0, 0);

			}else if (LogCounter <= 9.0 * SamplingFreq) {
				SetControlParameters(1, MEASUREMENT_ONLY, 0, 0,
				CURRENT_CONTROL, 0.75, 0, 0);

			}else if (LogCounter <= 10.0 * SamplingFreq) {
				SetControlParameters(1, MEASUREMENT_ONLY, 0, 0,
				CURRENT_CONTROL, 0.0, 0, 0);

			}else if (LogCounter <= 13.0 * SamplingFreq) {
				SetControlParameters(1, MEASUREMENT_ONLY, 0, 0,
				CURRENT_CONTROL, 1.0, 0, 0);

			} else if (LogCounter <= 14.0 * SamplingFreq) {
				SetControlParameters(1, MEASUREMENT_ONLY, 0, 0,
				CURRENT_CONTROL, 0.0, 0, 0);

			} else if (LogCounter <= 16.0 * SamplingFreq) {
				SetControlParameters(1, MEASUREMENT_ONLY, 0, 0,
				CURRENT_CONTROL, 0.75, 0, 0);

			} else if (LogCounter <= 17.0 * SamplingFreq) {
				SetControlParameters(1, MEASUREMENT_ONLY, 0, 0,
				CURRENT_CONTROL, 0.0, 0, 0);

			} else if (LogCounter <= 19.0 * SamplingFreq) {
				SetControlParameters(1, MEASUREMENT_ONLY, 0, 0,
				CURRENT_CONTROL, 0.5, 0, 0);

			} else if (LogCounter <= 20.0 * SamplingFreq) {
				SetControlParameters(1, MEASUREMENT_ONLY, 0, 0,
				CURRENT_CONTROL, 0.0, 0, 0);

			} else if (LogCounter <= 22.0 * SamplingFreq) {
				SetControlParameters(1, MEASUREMENT_ONLY, 0, 0,
				CURRENT_CONTROL, 0.25, 0, 0);

			} else if (LogCounter > 22.0 * SamplingFreq) {
				SetControlParameters(0, MEASUREMENT_ONLY, 0, 0,
							MEASUREMENT_ONLY, 0, 0, 0);
				StopActuators();
				ActiveCommand = IDLE_COMMAND;
				STPOS = 0;
				UARTTXLen = sprintf((char*) UARTTXBuffer, "Finished\n");
				HAL_UART_Transmit(&huart2, (uint8_t*) UARTTXBuffer, UARTTXLen, 100);
			}
			break;

		case LINEAR_POSITION_STEP_COMMAND:

			if (LogCounter == 0) {
				HAL_UART_DMAStop(&huart2);
				UARTTXLen = sprintf((char*) UARTTXBuffer, "STEP COMMAND\n");
				HAL_UART_Transmit(&huart2, (uint8_t*) UARTTXBuffer, UARTTXLen, 100);
				StartActuators();
				STPOS = 1;
			} else if (LogCounter <= 2.0 * SamplingFreq) {
				SetControlParameters(1, POSITION_CONTROL,
						2, 2,
									DONT_CHANGE_IT, 0, 0, 0);
			} else if (LogCounter > 2.0 * SamplingFreq) {

				SetControlParameters(0, MEASUREMENT_ONLY, 0, 0,
							MEASUREMENT_ONLY, 0, 0, 0);
				StopActuators();
				ActiveCommand = IDLE_COMMAND;
				STPOS = 0;
				UARTTXLen = sprintf((char*) UARTTXBuffer, "Finished\n");
				HAL_UART_Transmit(&huart2, (uint8_t*) UARTTXBuffer, UARTTXLen,
									100);
		    }
			break;

		case LINEAR_POSITION_RAMP_COMMAND:

			if (LogCounter == 0) {
				HAL_UART_DMAStop(&huart2);
				UARTTXLen = sprintf((char*) UARTTXBuffer, "RAMP COMMAND\n");
				HAL_UART_Transmit(&huart2, (uint8_t*) UARTTXBuffer, UARTTXLen, 100);
				StartActuators();
				STPOS = 1;
			} else if (LogCounter < 4.0 * SamplingFreq) {
				// 5.0f is home target
				float position_now  = ( 5.0f / (4.0f * SamplingFreq) ) * LogCounter;
				SetControlParameters(1, POSITION_CONTROL,
						position_now, 0,
									DONT_CHANGE_IT, 0, 0, 0);

			} else if (LogCounter >= 4.0 * SamplingFreq) {

				SetControlParameters(0, MEASUREMENT_ONLY, 0, 0,
							MEASUREMENT_ONLY, 0, 0, 0);
				StopActuators();
				ActiveCommand = IDLE_COMMAND;
				STPOS = 0;
				UARTTXLen = sprintf((char*) UARTTXBuffer, "Finished\n");
				HAL_UART_Transmit(&huart2, (uint8_t*) UARTTXBuffer, UARTTXLen,
									100);
		    }
			break;

		case CIRCLE_COMMAND:

			if (LogCounter == 0 && STPOS == 0) {
                if (ILC_ActiveProfileCommand != CIRCLE_COMMAND) {
                    // Never reuse corrections learned for a different path.
                    // Thus the first CIRC trial starts with zero ILC correction.
                    ILC_ResetCorrections();
                    ILC_ActiveProfileCommand = CIRCLE_COMMAND;
                }

				HAL_UART_DMAStop(&huart2);
				UARTTXLen = sprintf((char*) UARTTXBuffer, "COMMAND=CIRC\r\n");
				HAL_UART_Transmit(&huart2, (uint8_t*) UARTTXBuffer, UARTTXLen, 100);

                // The previous CIRC ramp ended at the circle point corresponding
                // to t = 0.25 s. Reuse that exact point for every trial's start/end.
                const float circleStartTime =
                    (float)CIRCLE_RAMP_SAMPLES / SamplingFreq;
                const float circleStartPhase = freq_circle * circleStartTime;
                circleStartX_mm = R_circle * sinf(circleStartPhase);
                circleStartY_mm = R_circle * cosf(circleStartPhase);

				STPOS = 1;
				StartActuators();

            } else if (LogCounter < CIRCLE_TOTAL_SAMPLES) {
                // Reference trajectory, error recording, and current logging
                // are handled in HAL_ADC_ConvCpltCallback().

			} else {

                SetControlParameters(0, MEASUREMENT_ONLY, 0.0f, 0.0f,
                                     MEASUREMENT_ONLY, 0.0f, 0.0f, 0);
                StopActuators();

                // Evaluate only the 1-second circular ILC segment. The 0.25 s
                // ramp and 0.5 s hold are deliberately excluded from learning.
                float errorRMS_X = ILC_CalculateRMS(ilcErrorX_um);
                float errorRMS_Y = ILC_CalculateRMS(ilcErrorY_um);
                float errorRMS_X_SteadyState = ILC_CalculateRMS_SteadyState(ilcErrorX_um);
                float errorRMS_Y_SteadyState = ILC_CalculateRMS_SteadyState(ilcErrorY_um);

#if ILC_USE_MODEL_INVERSE
                ModelInverseILC_Update();
#else
                PDILC_Update();
#endif

                float correctionPeakX = ILC_MaxCorrection(ilcCorrectionX_um);
                float correctionPeakY = ILC_MaxCorrection(ilcCorrectionY_um);

                ActiveCommand = IDLE_COMMAND;
                STPOS = 0;

                UARTTXLen = snprintf(
                    (char*)UARTTXBuffer,
                    UART_TX_BUFFER_SIZE - 1U,
                    "CIRC finished. X=%.4f mm, Y=%.4f mm, "
                    "RMS_X_full=%.6f mm, RMS_Y_full=%.6f mm, "
                    "RMS_X_samples_%u_to_%u=%.6f mm, "
                    "RMS_Y_samples_%u_to_%u=%.6f mm, "
                    "correction_peak_X_next=%.5f mm, correction_peak_Y_next=%.5f mm\r\n",
                    XActuator.MM.Position,
                    YActuator.MM.Position,
                    errorRMS_X,
                    errorRMS_Y,
                    (unsigned int)ILC_RMS_START_SAMPLE,
                    (unsigned int)ILC_TRIAL_SAMPLES,
                    errorRMS_X_SteadyState,
                    (unsigned int)ILC_RMS_START_SAMPLE,
                    (unsigned int)ILC_TRIAL_SAMPLES,
                    errorRMS_Y_SteadyState,
                    correctionPeakX,
                    correctionPeakY);

                HAL_UART_Transmit(&huart2, (uint8_t*)UARTTXBuffer, UARTTXLen, 100);
			}
			break;

		case PETAL_COMMAND:

			if (LogCounter == 0 && STPOS == 0) {
                if (ILC_ActiveProfileCommand != PETAL_COMMAND) {
                    // Start PETAL with zero correction when switching from another path.
                    // Repeated PETAL trials retain and improve their own correction profile.
                    ILC_ResetCorrections();
                    ILC_ActiveProfileCommand = PETAL_COMMAND;
                }

				HAL_UART_DMAStop(&huart2);
				UARTTXLen = sprintf((char*) UARTTXBuffer, "COMMAND=PETAL\r\n");
				HAL_UART_Transmit(&huart2, (uint8_t*) UARTTXBuffer, UARTTXLen, 100);

                // Calculate the exact PETAL point reached by the old 0.25-second ramp.
                const float petalRampTheta =
                    petal_turn * PETAL_RAMP_DURATION_S * petal_freq;
                petalStartX_mm = petal_dim * cosf(petal_num * petalRampTheta)
                                            * cosf(petalRampTheta);
                petalStartY_mm = petal_dim * cosf(petal_num * petalRampTheta)
                                            * sinf(petalRampTheta);

                STPOS = 1;
				StartActuators();

            } else if (LogCounter < PETAL_TOTAL_SAMPLES) {
                // PETAL reference, error recording, and current logging are in the ISR.

			} else {
                SetControlParameters(0, MEASUREMENT_ONLY, 0.0f, 0.0f,
                                     MEASUREMENT_ONLY, 0.0f, 0.0f, 0);
                StopActuators();

                // Evaluate only the repeatable 1-second PETAL segment.
                // The approach ramp and the hold at the PETAL start point are excluded.
                float errorRMS_X = ILC_CalculateRMS(ilcErrorX_um);
                float errorRMS_Y = ILC_CalculateRMS(ilcErrorY_um);
                float errorRMS_X_SteadyState = ILC_CalculateRMS_SteadyState(ilcErrorX_um);
                float errorRMS_Y_SteadyState = ILC_CalculateRMS_SteadyState(ilcErrorY_um);

#if ILC_USE_MODEL_INVERSE
                ModelInverseILC_Update();
#else
                PDILC_Update();
#endif
                ILC_ActiveProfileCommand = PETAL_COMMAND;

                float correctionPeakX = ILC_MaxCorrection(ilcCorrectionX_um);
                float correctionPeakY = ILC_MaxCorrection(ilcCorrectionY_um);

                ActiveCommand = IDLE_COMMAND;
                STPOS = 0;

                UARTTXLen = snprintf(
                    (char*)UARTTXBuffer,
                    UART_TX_BUFFER_SIZE - 1U,
                    "PETAL finished. X=%.4f mm, Y=%.4f mm, "
                    "RMS_X_full=%.6f mm, RMS_Y_full=%.6f mm, "
                    "RMS_X_samples_%u_to_%u=%.6f mm, "
                    "RMS_Y_samples_%u_to_%u=%.6f mm, "
                    "correction_peak_X_next=%.5f mm, correction_peak_Y_next=%.5f mm\r\n",
                    XActuator.MM.Position,
                    YActuator.MM.Position,
                    errorRMS_X,
                    errorRMS_Y,
                    (unsigned int)ILC_RMS_START_SAMPLE,
                    (unsigned int)ILC_TRIAL_SAMPLES,
                    errorRMS_X_SteadyState,
                    (unsigned int)ILC_RMS_START_SAMPLE,
                    (unsigned int)ILC_TRIAL_SAMPLES,
                    errorRMS_Y_SteadyState,
                    correctionPeakX,
                    correctionPeakY);

                HAL_UART_Transmit(&huart2, (uint8_t*)UARTTXBuffer, UARTTXLen, 100);
			}
			break;

        case LISSAJOUS12_COMMAND:
        case LISSAJOUS23_COMMAND: {
            const uint8_t isRatio12 = (ActiveCommand == LISSAJOUS12_COMMAND);
            const float lissFx_Hz = isRatio12 ? LISSAJOUS12_FX_HZ : LISSAJOUS23_FX_HZ;
            const float lissFy_Hz = isRatio12 ? LISSAJOUS12_FY_HZ : LISSAJOUS23_FY_HZ;
            const char *lissName = isRatio12 ? "LIS12" : "LIS23";

            if (LogCounter == 0 && STPOS == 0) {
                if (ILC_ActiveProfileCommand != ActiveCommand) {
                    // Never reuse a correction profile between different Lissajous ratios.
                    ILC_ResetCorrections();
                    ILC_ActiveProfileCommand = ActiveCommand;
                }

                HAL_UART_DMAStop(&huart2);
                UARTTXLen = snprintf((char *)UARTTXBuffer, UART_TX_BUFFER_SIZE - 1U,
                                     "COMMAND=%s\r\n", lissName);
                HAL_UART_Transmit(&huart2, (uint8_t *)UARTTXBuffer, UARTTXLen, 100);

                // Compute the exact reference point at the end of the unlearned ramp.
                const float rampEndTime = (float)LISSAJOUS_RAMP_SAMPLES / SamplingFreq;
                lissajousStartX_mm = LISSAJOUS_A_X_MM *
                    sinf(2.0f * (float)M_PI * lissFx_Hz * rampEndTime);
                lissajousStartY_mm = LISSAJOUS_A_Y_MM *
                    sinf(2.0f * (float)M_PI * lissFy_Hz * rampEndTime + LISSAJOUS_PHASE_Y_RAD);

                STPOS = 1;
                StartActuators();

            } else if (LogCounter < LISSAJOUS_TOTAL_SAMPLES) {
                // Lissajous reference, error recording, and current logging run in the ISR.

            } else {
                SetControlParameters(0, MEASUREMENT_ONLY, 0.0f, 0.0f,
                                     MEASUREMENT_ONLY, 0.0f, 0.0f, 0);
                StopActuators();

                float errorRMS_X = ILC_CalculateRMS(ilcErrorX_um);
                float errorRMS_Y = ILC_CalculateRMS(ilcErrorY_um);
                float errorRMS_X_SteadyState = ILC_CalculateRMS_SteadyState(ilcErrorX_um);
                float errorRMS_Y_SteadyState = ILC_CalculateRMS_SteadyState(ilcErrorY_um);

#if ILC_USE_MODEL_INVERSE
                ModelInverseILC_Update();
#else
                PDILC_Update();
#endif
                ILC_ActiveProfileCommand = ActiveCommand;

                float correctionPeakX = ILC_MaxCorrection(ilcCorrectionX_um);
                float correctionPeakY = ILC_MaxCorrection(ilcCorrectionY_um);

                ActiveCommand = IDLE_COMMAND;
                STPOS = 0;

                UARTTXLen = snprintf(
                    (char *)UARTTXBuffer,
                    UART_TX_BUFFER_SIZE - 1U,
                    "%s finished. X=%.4f mm, Y=%.4f mm, "
                    "RMS_X_full=%.6f mm, RMS_Y_full=%.6f mm, "
                    "RMS_X_samples_%u_to_%u=%.6f mm, "
                    "RMS_Y_samples_%u_to_%u=%.6f mm, "
                    "correction_peak_X_next=%.5f mm, correction_peak_Y_next=%.5f mm\r\n",
                    lissName,
                    XActuator.MM.Position,
                    YActuator.MM.Position,
                    errorRMS_X,
                    errorRMS_Y,
                    (unsigned int)ILC_RMS_START_SAMPLE,
                    (unsigned int)ILC_TRIAL_SAMPLES,
                    errorRMS_X_SteadyState,
                    (unsigned int)ILC_RMS_START_SAMPLE,
                    (unsigned int)ILC_TRIAL_SAMPLES,
                    errorRMS_Y_SteadyState,
                    correctionPeakX,
                    correctionPeakY);
                HAL_UART_Transmit(&huart2, (uint8_t *)UARTTXBuffer, UARTTXLen, 100);
            }
            break;
        }

//		case EPICYCLOID_COMMAND:
//
//		    if (LogCounter == 0) {
//		        HAL_UART_DMAStop(&huart2);
//		        UARTTXLen = sprintf((char*) UARTTXBuffer, "EPICYCLOID COMMAND\n");
//		        HAL_UART_Transmit(&huart2, (uint8_t*) UARTTXBuffer, UARTTXLen, 100);
//		        StartActuators();
//		        STPOS = 1;
//
//		    } else if (LogCounter < 0.25f * SamplingFreq) {   // RAMP 0 → 0.25 s
//
//		        float t_ramp_end  = 0.25f;
//		        float theta_ramp  = epi_turns * t_ramp_end * epi_freq;
//		        float target_X    = epi_R * cosf(theta_ramp) + epi_r * cosf(epi_n * theta_ramp);
//		        float target_Y    = epi_R * sinf(theta_ramp) + epi_r * sinf(epi_n * theta_ramp);
//
//		        float position_start_X = (target_X / (0.25f * SamplingFreq)) * (LogCounter+1);
//		        float position_start_Y = (target_Y / (0.25f * SamplingFreq)) * (LogCounter+1);
//
//		        SetControlParameters(1, POSITION_CONTROL,
//		                             position_start_X, position_start_Y,
//		                             DONT_CHANGE_IT, 0, 0, 0);
//
//		    } else if (LogCounter <= 4 * SamplingFreq) {   // TRAJECTORY 0.25 → 4 s
//
//		        float t     = (float)(LogCounter+1) / SamplingFreq;
//		        float theta = epi_turns * t * epi_freq;
//		        float x = epi_R * cosf(theta) + epi_r * cosf(epi_n * theta);
//		        float y = epi_R * sinf(theta) + epi_r * sinf(epi_n * theta);
//
//		        SetControlParameters(1, POSITION_CONTROL, x, y,
//		                             DONT_CHANGE_IT, 0, 0, 0);
//
//		    } else {   // STOP
//		        SetControlParameters(0, MEASUREMENT_ONLY, 0, 0,
//		                             MEASUREMENT_ONLY, 0, 0, 0);
//		        StopActuators();
//		        ActiveCommand = IDLE_COMMAND;
//		        STPOS = 0;
//		        UARTTXLen = sprintf((char*) UARTTXBuffer, "Finished\n");
//		        HAL_UART_Transmit(&huart2, (uint8_t*) UARTTXBuffer, UARTTXLen, 100);
//		    }
//		    break;

		case SQUARE_COMMAND:

		    if (LogCounter == 0) {
		        HAL_UART_DMAStop(&huart2);
		        UARTTXLen = sprintf((char*) UARTTXBuffer, "SQUARE COMMAND\n");
		        HAL_UART_Transmit(&huart2, (uint8_t*) UARTTXBuffer, UARTTXLen, 100);
		        StartActuators();
		        STPOS = 1;
		    } else if (LogCounter < 0.25f * SamplingFreq) {

		        uint32_t square_time = 0.25f * SamplingFreq ;

		        uint32_t period_ticks = (uint32_t)( SamplingFreq / freq_square);
		        uint32_t ticks_per_side = period_ticks / 4;
		        uint32_t ticks_in_side = square_time % ticks_per_side;
		        float progress_dummy = (float)ticks_in_side / (float)ticks_per_side; // 0..1 along side
		        uint32_t corner = (square_time / ticks_per_side) % 4;

		        float pos_x, pos_y;

		        switch (corner) {
		            case 0: // Top edge: (A, A) → (-A, A)
		                pos_x =  amplitude_square - 2.0f * amplitude_square * progress_dummy;
		                pos_y =  amplitude_square;
		                break;
		            case 1: // Left edge: (-A, A) → (-A, -A)
		                pos_x = -1.0f*amplitude_square;
		                pos_y =  amplitude_square - 2.0f * amplitude_square * progress_dummy;
		                break;
		            case 2: // Bottom edge: (-A, -A) → (A, -A)
		                pos_x = -1.0f*amplitude_square + 2.0f * amplitude_square * progress_dummy;
		                pos_y = -1.0f*amplitude_square;
		                break;
		            case 3: // Right edge: (A, -A) → (A, A)
		                pos_x =  amplitude_square;
		                pos_y = -1.0f*amplitude_square + 2.0f * amplitude_square * progress_dummy;
		                break;
		        }

				float position_start_X  = ( pos_x  / square_time ) * LogCounter;
				float position_start_Y  = ( pos_y / square_time ) * LogCounter;

				SetControlParameters(1, POSITION_CONTROL,
						position_start_X, position_start_Y,
									DONT_CHANGE_IT, 0, 0, 0);

			} else if (LogCounter < 3 * SamplingFreq) {

		        // ticks for a full square
		        uint32_t period_ticks = (uint32_t)( SamplingFreq / freq_square);
		        uint32_t ticks_per_side = period_ticks / 4;

		        uint32_t corner = (LogCounter / ticks_per_side) % 4;
		        uint32_t ticks_in_side = LogCounter % ticks_per_side;
		        float progress = (float)ticks_in_side / (float)ticks_per_side; // 0..1 along side

		        float pos_x, pos_y;

		        switch (corner) {
		            case 0: // Top edge: (A, A) → (-A, A)
		                pos_x =  amplitude_square - 2.0f * amplitude_square * progress;
		                pos_y =  amplitude_square;
		                break;
		            case 1: // Left edge: (-A, A) → (-A, -A)
		                pos_x = -1.0f*amplitude_square;
		                pos_y =  amplitude_square - 2.0f * amplitude_square * progress;
		                break;
		            case 2: // Bottom edge: (-A, -A) → (A, -A)
		                pos_x = -1.0f*amplitude_square + 2.0f * amplitude_square * progress;
		                pos_y = -1.0f*amplitude_square;
		                break;
		            case 3: // Right edge: (A, -A) → (A, A)
		                pos_x =  amplitude_square;
		                pos_y = -1.0f*amplitude_square + 2.0f * amplitude_square * progress;
		                break;
		        }

		        SetControlParameters(1, POSITION_CONTROL,
		                             pos_x, pos_y,
		                             DONT_CHANGE_IT, 0, 0, 0);
		    }
		    else if (LogCounter >= 3 * SamplingFreq) {
		        SetControlParameters(0, MEASUREMENT_ONLY, 0, 0,
		                             MEASUREMENT_ONLY, 0, 0, 0);
		        StopActuators();
		        ActiveCommand = IDLE_COMMAND;
		        STPOS = 0;
		        UARTTXLen = sprintf((char*) UARTTXBuffer, "Finished\n");
		        HAL_UART_Transmit(&huart2, (uint8_t*) UARTTXBuffer, UARTTXLen, 100);
		    }

		    break;

		case TRIANGLE_COMMAND:

		    if (LogCounter == 0) {
		        HAL_UART_DMAStop(&huart2);
		        UARTTXLen = sprintf((char*) UARTTXBuffer, "TRIANGLE COMMAND\n");
		        HAL_UART_Transmit(&huart2, (uint8_t*) UARTTXBuffer, UARTTXLen, 100);
		        StartActuators();
		        STPOS = 1;
		    }else if (LogCounter < 0.25 * SamplingFreq) {

		    	uint32_t triangle_time = 0.25f * SamplingFreq ;
		        const float height = amplitude_triangle * sqrtf(3.0f);
		        // Vertices (centered at origin)
		        float vx[3] = { 0.0f,     -amplitude_triangle,  amplitude_triangle };
		        float vy[3] = { height/2.0f, -height/2.0f, -height/2.0f };

		        // ticks for a full triangle
		        uint32_t period_ticks = (uint32_t)(SamplingFreq / freq_triangle);
		        uint32_t ticks_per_side = period_ticks / 3;

		        uint32_t side = (triangle_time / ticks_per_side) % 3;
		        uint32_t ticks_in_side = triangle_time % ticks_per_side;
		        float progress = (float)ticks_in_side / (float)ticks_per_side; // 0..1 along side

		        // Start and end vertex for this side
		        uint32_t next_vertex = (side + 1) % 3;

		        // Linear interpolation between vertices
		        float pos_x = vx[side] + (vx[next_vertex] - vx[side]) * progress;
		        float pos_y = vy[side] + (vy[next_vertex] - vy[side]) * progress;

		        float pos_x_start = ( pos_x / triangle_time ) * LogCounter;
		        float pos_y_start = ( pos_y / triangle_time ) * LogCounter;
		        SetControlParameters(1, POSITION_CONTROL,
		        		pos_x_start, pos_y_start,
		                             DONT_CHANGE_IT, 0, 0, 0);

		    }else if (LogCounter < 3 * SamplingFreq) {

		        // Triangle geometry
		        // Height of equilateral triangle
		        const float height = amplitude_triangle * sqrtf(3.0f);
		        // Vertices (centered at origin)
		        float vx[3] = { 0.0f,     -amplitude_triangle,  amplitude_triangle };
		        float vy[3] = { height/2.0f, -height/2.0f, -height/2.0f };

		        // ticks for a full triangle
		        uint32_t period_ticks = (uint32_t)(SamplingFreq / freq_triangle);
		        uint32_t ticks_per_side = period_ticks / 3;

		        uint32_t side = (LogCounter / ticks_per_side) % 3;
		        uint32_t ticks_in_side = LogCounter % ticks_per_side;
		        float progress = (float)ticks_in_side / (float)ticks_per_side; // 0..1 along side

		        // Start and end vertex for this side
		        uint32_t next_vertex = (side + 1) % 3;

		        // Linear interpolation between vertices
		        float pos_x = vx[side] + (vx[next_vertex] - vx[side]) * progress;
		        float pos_y = vy[side] + (vy[next_vertex] - vy[side]) * progress;

		        SetControlParameters(1, POSITION_CONTROL,
		                             pos_x, pos_y,
		                             DONT_CHANGE_IT, 0, 0, 0);
		    }
		    else if (LogCounter >= 3 * SamplingFreq) {
		        SetControlParameters(0, MEASUREMENT_ONLY, 0, 0,
		                             MEASUREMENT_ONLY, 0, 0, 0);
		        StopActuators();
		        ActiveCommand = IDLE_COMMAND;
		        STPOS = 0;
		        UARTTXLen = sprintf((char*) UARTTXBuffer, "Finished\n");
		        HAL_UART_Transmit(&huart2, (uint8_t*) UARTTXBuffer, UARTTXLen, 100);
		    }

		    break;

			////////////////////////////////////////////////////////////////////////////////
			/*------------------------- END OF ACTUATION COMMANDS ---------------------------*/
			////////////////////////////////////////////////////////////////////////////////
		case MEASUREMENT_COMMAND:
			UARTTXLen = sprintf((char*) UARTTXBuffer, "Measurement Command\n");
			HAL_UART_Transmit_DMA(&huart2, (uint8_t*) UARTTXBuffer, UARTTXLen);

			SetControlParameters(1, MEASUREMENT_ONLY, 0, 0,
			MEASUREMENT_ONLY, 0, 0, 0);

			StartActuators();

			ActiveCommand = IDLE_COMMAND;
			break;

		case STOP_COMMAND:
			HAL_UART_DMAStop(&huart2);
			UARTTXLen = sprintf((char*) UARTTXBuffer, "STOP Command\n");
			HAL_UART_Transmit(&huart2, (uint8_t*) UARTTXBuffer, UARTTXLen, 100);
			StopActuators();
			STPOS = 0; // Allow the next SINX/SINY/CIRC command to start after an abort.
			UARTTXLen = sprintf((char*) UARTTXBuffer, "Finished\n");
			HAL_UART_Transmit(&huart2, (uint8_t*) UARTTXBuffer, UARTTXLen, 100);
			ActiveCommand = IDLE_COMMAND;
			DataLogStatus = LOG_IDLE;
			break;
		}

//		switch (DataLogStatus) {
//
//		case LOG_NEW_DATA_READY:
//			HAL_UART_DMAStop(&huart2);
//			UARTTXLen = snprintf((char*) UARTTXBuffer,
//			UART_TX_BUFFER_SIZE - 1, "%.2f,%.2f,%.2f\n",
//			YActuator.MC.ControlEffort[0],YActuator.EC.Error[0],YActuator.EM.Current);
//
//
//			HAL_UART_Transmit_DMA(&huart2, (uint8_t*) UARTTXBuffer, UARTTXLen);
//
//			DataLogStatus = LOG_IDLE;
//			break;
//
//		}
	}
    /* USER CODE END WHILE */

}

void SystemClock_Config(void)
{
  RCC_OscInitTypeDef RCC_OscInitStruct = {0};
  RCC_ClkInitTypeDef RCC_ClkInitStruct = {0};
  RCC_PeriphCLKInitTypeDef PeriphClkInit = {0};

  /** Initializes the RCC Oscillators according to the specified parameters
  * in the RCC_OscInitTypeDef structure.
  */
  RCC_OscInitStruct.OscillatorType = RCC_OSCILLATORTYPE_HSI;
  RCC_OscInitStruct.HSIState = RCC_HSI_ON;
  RCC_OscInitStruct.HSICalibrationValue = RCC_HSICALIBRATION_DEFAULT;
  RCC_OscInitStruct.PLL.PLLState = RCC_PLL_ON;
  RCC_OscInitStruct.PLL.PLLSource = RCC_PLLSOURCE_HSI;
  RCC_OscInitStruct.PLL.PLLMUL = RCC_PLL_MUL9;
  RCC_OscInitStruct.PLL.PREDIV = RCC_PREDIV_DIV1;
  if (HAL_RCC_OscConfig(&RCC_OscInitStruct) != HAL_OK)
  {
    Error_Handler();
  }

  /** Initializes the CPU, AHB and APB buses clocks
  */
  RCC_ClkInitStruct.ClockType = RCC_CLOCKTYPE_HCLK|RCC_CLOCKTYPE_SYSCLK
                              |RCC_CLOCKTYPE_PCLK1|RCC_CLOCKTYPE_PCLK2;
  RCC_ClkInitStruct.SYSCLKSource = RCC_SYSCLKSOURCE_PLLCLK;
  RCC_ClkInitStruct.AHBCLKDivider = RCC_SYSCLK_DIV1;
  RCC_ClkInitStruct.APB1CLKDivider = RCC_HCLK_DIV2;
  RCC_ClkInitStruct.APB2CLKDivider = RCC_HCLK_DIV1;

  if (HAL_RCC_ClockConfig(&RCC_ClkInitStruct, FLASH_LATENCY_1) != HAL_OK)
  {
    Error_Handler();
  }
  PeriphClkInit.PeriphClockSelection = RCC_PERIPHCLK_USART2|RCC_PERIPHCLK_TIM1
                              |RCC_PERIPHCLK_ADC12|RCC_PERIPHCLK_ADC34
                              |RCC_PERIPHCLK_TIM34;
  PeriphClkInit.Usart2ClockSelection = RCC_USART2CLKSOURCE_PCLK1;
  PeriphClkInit.Adc12ClockSelection = RCC_ADC12PLLCLK_DIV1;
  PeriphClkInit.Adc34ClockSelection = RCC_ADC34PLLCLK_DIV1;
  PeriphClkInit.Tim1ClockSelection = RCC_TIM1CLK_HCLK;
  PeriphClkInit.Tim34ClockSelection = RCC_TIM34CLK_HCLK;
  if (HAL_RCCEx_PeriphCLKConfig(&PeriphClkInit) != HAL_OK)
  {
    Error_Handler();
  }
}

static void MX_ADC1_Init(void)
{

  ADC_MultiModeTypeDef multimode = {0};
  ADC_ChannelConfTypeDef sConfig = {0};

  /** Common config
  */
  hadc1.Instance = ADC1;
  hadc1.Init.ClockPrescaler = ADC_CLOCK_ASYNC_DIV1;
  hadc1.Init.Resolution = ADC_RESOLUTION_12B;
  hadc1.Init.ScanConvMode = ADC_SCAN_DISABLE;
  hadc1.Init.ContinuousConvMode = ENABLE;
  hadc1.Init.DiscontinuousConvMode = DISABLE;
  hadc1.Init.ExternalTrigConvEdge = ADC_EXTERNALTRIGCONVEDGE_NONE;
  hadc1.Init.ExternalTrigConv = ADC_SOFTWARE_START;
  hadc1.Init.DataAlign = ADC_DATAALIGN_RIGHT;
  hadc1.Init.NbrOfConversion = 1;
  hadc1.Init.DMAContinuousRequests = DISABLE;
  hadc1.Init.EOCSelection = ADC_EOC_SINGLE_CONV;
  hadc1.Init.LowPowerAutoWait = DISABLE;
  hadc1.Init.Overrun = ADC_OVR_DATA_OVERWRITTEN;
  if (HAL_ADC_Init(&hadc1) != HAL_OK)
  {
    Error_Handler();
  }

  /** Configure the ADC multi-mode
  */
  multimode.Mode = ADC_MODE_INDEPENDENT;
  if (HAL_ADCEx_MultiModeConfigChannel(&hadc1, &multimode) != HAL_OK)
  {
    Error_Handler();
  }

  /** Configure Regular Channel
  */
  sConfig.Channel = ADC_CHANNEL_14;
  sConfig.Rank = ADC_REGULAR_RANK_1;
  sConfig.SingleDiff = ADC_SINGLE_ENDED;
  sConfig.SamplingTime = ADC_SAMPLETIME_1CYCLE_5;
  sConfig.OffsetNumber = ADC_OFFSET_NONE;
  sConfig.Offset = 0;
  if (HAL_ADC_ConfigChannel(&hadc1, &sConfig) != HAL_OK)
  {
    Error_Handler();
  }

}

static void MX_ADC2_Init(void)
{

  ADC_ChannelConfTypeDef sConfig = {0};

  /** Common config
  */
  hadc2.Instance = ADC2;
  hadc2.Init.ClockPrescaler = ADC_CLOCK_ASYNC_DIV1;
  hadc2.Init.Resolution = ADC_RESOLUTION_12B;
  hadc2.Init.ScanConvMode = ADC_SCAN_DISABLE;
  hadc2.Init.ContinuousConvMode = DISABLE;
  hadc2.Init.DiscontinuousConvMode = DISABLE;
  hadc2.Init.ExternalTrigConvEdge = ADC_EXTERNALTRIGCONVEDGE_RISING;
  hadc2.Init.ExternalTrigConv = ADC_EXTERNALTRIGCONV_T1_TRGO;
  hadc2.Init.DataAlign = ADC_DATAALIGN_RIGHT;
  hadc2.Init.NbrOfConversion = 1;
  hadc2.Init.DMAContinuousRequests = DISABLE;
  hadc2.Init.EOCSelection = ADC_EOC_SINGLE_CONV;
  hadc2.Init.LowPowerAutoWait = DISABLE;
  hadc2.Init.Overrun = ADC_OVR_DATA_OVERWRITTEN;
  if (HAL_ADC_Init(&hadc2) != HAL_OK)
  {
    Error_Handler();
  }

  /** Configure Regular Channel
  */
  sConfig.Channel = ADC_CHANNEL_3;
  sConfig.Rank = ADC_REGULAR_RANK_1;
  sConfig.SingleDiff = ADC_SINGLE_ENDED;
  sConfig.SamplingTime = ADC_SAMPLETIME_61CYCLES_5;
  sConfig.OffsetNumber = ADC_OFFSET_NONE;
  sConfig.Offset = 0;
  if (HAL_ADC_ConfigChannel(&hadc2, &sConfig) != HAL_OK)
  {
    Error_Handler();
  }

}

static void MX_ADC3_Init(void)
{

  ADC_MultiModeTypeDef multimode = {0};
  ADC_ChannelConfTypeDef sConfig = {0};

  /** Common config
  */
  hadc3.Instance = ADC3;
  hadc3.Init.ClockPrescaler = ADC_CLOCK_ASYNC_DIV1;
  hadc3.Init.Resolution = ADC_RESOLUTION_12B;
  hadc3.Init.ScanConvMode = ADC_SCAN_DISABLE;
  hadc3.Init.ContinuousConvMode = DISABLE;
  hadc3.Init.DiscontinuousConvMode = DISABLE;
  hadc3.Init.ExternalTrigConvEdge = ADC_EXTERNALTRIGCONVEDGE_RISING;
  hadc3.Init.ExternalTrigConv = ADC_EXTERNALTRIGCONV_T1_TRGO;
  hadc3.Init.DataAlign = ADC_DATAALIGN_RIGHT;
  hadc3.Init.NbrOfConversion = 1;
  hadc3.Init.DMAContinuousRequests = DISABLE;
  hadc3.Init.EOCSelection = ADC_EOC_SINGLE_CONV;
  hadc3.Init.LowPowerAutoWait = DISABLE;
  hadc3.Init.Overrun = ADC_OVR_DATA_OVERWRITTEN;
  if (HAL_ADC_Init(&hadc3) != HAL_OK)
  {
    Error_Handler();
  }

  /** Configure the ADC multi-mode
  */
  multimode.Mode = ADC_MODE_INDEPENDENT;
  if (HAL_ADCEx_MultiModeConfigChannel(&hadc3, &multimode) != HAL_OK)
  {
    Error_Handler();
  }

  /** Configure Regular Channel
  */
  sConfig.Channel = ADC_CHANNEL_1;
  sConfig.Rank = ADC_REGULAR_RANK_1;
  sConfig.SingleDiff = ADC_SINGLE_ENDED;
  sConfig.SamplingTime = ADC_SAMPLETIME_19CYCLES_5;
  sConfig.OffsetNumber = ADC_OFFSET_NONE;
  sConfig.Offset = 0;
  if (HAL_ADC_ConfigChannel(&hadc3, &sConfig) != HAL_OK)
  {
    Error_Handler();
  }

}

static void MX_OPAMP2_Init(void)
{

  hopamp2.Instance = OPAMP2;
  hopamp2.Init.Mode = OPAMP_FOLLOWER_MODE;
  hopamp2.Init.NonInvertingInput = OPAMP_NONINVERTINGINPUT_IO0;
  hopamp2.Init.TimerControlledMuxmode = OPAMP_TIMERCONTROLLEDMUXMODE_DISABLE;
  hopamp2.Init.UserTrimming = OPAMP_TRIMMING_FACTORY;
  if (HAL_OPAMP_Init(&hopamp2) != HAL_OK)
  {
    Error_Handler();
  }

}

static void MX_OPAMP3_Init(void)
{

  hopamp3.Instance = OPAMP3;
  hopamp3.Init.Mode = OPAMP_FOLLOWER_MODE;
  hopamp3.Init.NonInvertingInput = OPAMP_NONINVERTINGINPUT_IO0;
  hopamp3.Init.TimerControlledMuxmode = OPAMP_TIMERCONTROLLEDMUXMODE_DISABLE;
  hopamp3.Init.UserTrimming = OPAMP_TRIMMING_FACTORY;
  if (HAL_OPAMP_Init(&hopamp3) != HAL_OK)
  {
    Error_Handler();
  }

}

static void MX_TIM1_Init(void)
{

  TIM_ClockConfigTypeDef sClockSourceConfig = {0};
  TIM_MasterConfigTypeDef sMasterConfig = {0};
  TIM_OC_InitTypeDef sConfigOC = {0};
  TIM_BreakDeadTimeConfigTypeDef sBreakDeadTimeConfig = {0};

  htim1.Instance = TIM1;
  htim1.Init.Prescaler = 0;
  htim1.Init.CounterMode = TIM_COUNTERMODE_CENTERALIGNED1;
  htim1.Init.Period = 7200-1;
  htim1.Init.ClockDivision = TIM_CLOCKDIVISION_DIV1;
  htim1.Init.RepetitionCounter = 1;
  htim1.Init.AutoReloadPreload = TIM_AUTORELOAD_PRELOAD_DISABLE;
  if (HAL_TIM_Base_Init(&htim1) != HAL_OK)
  {
    Error_Handler();
  }
  sClockSourceConfig.ClockSource = TIM_CLOCKSOURCE_INTERNAL;
  if (HAL_TIM_ConfigClockSource(&htim1, &sClockSourceConfig) != HAL_OK)
  {
    Error_Handler();
  }
  if (HAL_TIM_PWM_Init(&htim1) != HAL_OK)
  {
    Error_Handler();
  }
  sMasterConfig.MasterOutputTrigger = TIM_TRGO_UPDATE;
  sMasterConfig.MasterOutputTrigger2 = TIM_TRGO2_RESET;
  sMasterConfig.MasterSlaveMode = TIM_MASTERSLAVEMODE_DISABLE;
  if (HAL_TIMEx_MasterConfigSynchronization(&htim1, &sMasterConfig) != HAL_OK)
  {
    Error_Handler();
  }
  sConfigOC.OCMode = TIM_OCMODE_PWM1;
  sConfigOC.Pulse = 0;
  sConfigOC.OCPolarity = TIM_OCPOLARITY_HIGH;
  sConfigOC.OCNPolarity = TIM_OCNPOLARITY_HIGH;
  sConfigOC.OCFastMode = TIM_OCFAST_DISABLE;
  sConfigOC.OCIdleState = TIM_OCIDLESTATE_RESET;
  sConfigOC.OCNIdleState = TIM_OCNIDLESTATE_RESET;
  if (HAL_TIM_PWM_ConfigChannel(&htim1, &sConfigOC, TIM_CHANNEL_1) != HAL_OK)
  {
    Error_Handler();
  }
  if (HAL_TIM_PWM_ConfigChannel(&htim1, &sConfigOC, TIM_CHANNEL_2) != HAL_OK)
  {
    Error_Handler();
  }
  if (HAL_TIM_PWM_ConfigChannel(&htim1, &sConfigOC, TIM_CHANNEL_3) != HAL_OK)
  {
    Error_Handler();
  }
  if (HAL_TIM_PWM_ConfigChannel(&htim1, &sConfigOC, TIM_CHANNEL_4) != HAL_OK)
  {
    Error_Handler();
  }
  sBreakDeadTimeConfig.OffStateRunMode = TIM_OSSR_DISABLE;
  sBreakDeadTimeConfig.OffStateIDLEMode = TIM_OSSI_DISABLE;
  sBreakDeadTimeConfig.LockLevel = TIM_LOCKLEVEL_OFF;
  sBreakDeadTimeConfig.DeadTime = 0;
  sBreakDeadTimeConfig.BreakState = TIM_BREAK_DISABLE;
  sBreakDeadTimeConfig.BreakPolarity = TIM_BREAKPOLARITY_HIGH;
  sBreakDeadTimeConfig.BreakFilter = 0;
  sBreakDeadTimeConfig.Break2State = TIM_BREAK2_DISABLE;
  sBreakDeadTimeConfig.Break2Polarity = TIM_BREAK2POLARITY_HIGH;
  sBreakDeadTimeConfig.Break2Filter = 0;
  sBreakDeadTimeConfig.AutomaticOutput = TIM_AUTOMATICOUTPUT_DISABLE;
  if (HAL_TIMEx_ConfigBreakDeadTime(&htim1, &sBreakDeadTimeConfig) != HAL_OK)
  {
    Error_Handler();
  }
  HAL_TIM_MspPostInit(&htim1);

}

static void MX_TIM3_Init(void)
{

  TIM_Encoder_InitTypeDef sConfig = {0};
  TIM_MasterConfigTypeDef sMasterConfig = {0};

  htim3.Instance = TIM3;
  htim3.Init.Prescaler = 0;
  htim3.Init.CounterMode = TIM_COUNTERMODE_UP;
  htim3.Init.Period = 65535;
  htim3.Init.ClockDivision = TIM_CLOCKDIVISION_DIV1;
  htim3.Init.AutoReloadPreload = TIM_AUTORELOAD_PRELOAD_DISABLE;
  sConfig.EncoderMode = TIM_ENCODERMODE_TI12;
  sConfig.IC1Polarity = TIM_ICPOLARITY_RISING;
  sConfig.IC1Selection = TIM_ICSELECTION_DIRECTTI;
  sConfig.IC1Prescaler = TIM_ICPSC_DIV1;
  sConfig.IC1Filter = 0;
  sConfig.IC2Polarity = TIM_ICPOLARITY_FALLING;
  sConfig.IC2Selection = TIM_ICSELECTION_DIRECTTI;
  sConfig.IC2Prescaler = TIM_ICPSC_DIV1;
  sConfig.IC2Filter = 0;
  if (HAL_TIM_Encoder_Init(&htim3, &sConfig) != HAL_OK)
  {
    Error_Handler();
  }
  sMasterConfig.MasterOutputTrigger = TIM_TRGO_RESET;
  sMasterConfig.MasterSlaveMode = TIM_MASTERSLAVEMODE_DISABLE;
  if (HAL_TIMEx_MasterConfigSynchronization(&htim3, &sMasterConfig) != HAL_OK)
  {
    Error_Handler();
  }

}

static void MX_TIM4_Init(void)
{

  TIM_Encoder_InitTypeDef sConfig = {0};
  TIM_MasterConfigTypeDef sMasterConfig = {0};

  htim4.Instance = TIM4;
  htim4.Init.Prescaler = 0;
  htim4.Init.CounterMode = TIM_COUNTERMODE_UP;
  htim4.Init.Period = 65535;
  htim4.Init.ClockDivision = TIM_CLOCKDIVISION_DIV1;
  htim4.Init.AutoReloadPreload = TIM_AUTORELOAD_PRELOAD_DISABLE;
  sConfig.EncoderMode = TIM_ENCODERMODE_TI12;
  sConfig.IC1Polarity = TIM_ICPOLARITY_RISING;
  sConfig.IC1Selection = TIM_ICSELECTION_DIRECTTI;
  sConfig.IC1Prescaler = TIM_ICPSC_DIV1;
  sConfig.IC1Filter = 0;
  sConfig.IC2Polarity = TIM_ICPOLARITY_RISING;
  sConfig.IC2Selection = TIM_ICSELECTION_DIRECTTI;
  sConfig.IC2Prescaler = TIM_ICPSC_DIV1;
  sConfig.IC2Filter = 0;
  if (HAL_TIM_Encoder_Init(&htim4, &sConfig) != HAL_OK)
  {
    Error_Handler();
  }
  sMasterConfig.MasterOutputTrigger = TIM_TRGO_RESET;
  sMasterConfig.MasterSlaveMode = TIM_MASTERSLAVEMODE_DISABLE;
  if (HAL_TIMEx_MasterConfigSynchronization(&htim4, &sMasterConfig) != HAL_OK)
  {
    Error_Handler();
  }

}

static void MX_USART2_UART_Init(void)
{

  huart2.Instance = USART2;
  huart2.Init.BaudRate = 1000000;
  huart2.Init.WordLength = UART_WORDLENGTH_8B;
  huart2.Init.StopBits = UART_STOPBITS_1;
  huart2.Init.Parity = UART_PARITY_NONE;
  huart2.Init.Mode = UART_MODE_TX_RX;
  huart2.Init.HwFlowCtl = UART_HWCONTROL_NONE;
  huart2.Init.OverSampling = UART_OVERSAMPLING_16;
  huart2.Init.OneBitSampling = UART_ONE_BIT_SAMPLE_DISABLE;
  huart2.AdvancedInit.AdvFeatureInit = UART_ADVFEATURE_NO_INIT;
  if (HAL_UART_Init(&huart2) != HAL_OK)
  {
    Error_Handler();
  }

}

static void MX_DMA_Init(void)
{

  /* DMA controller clock enable */
  __HAL_RCC_DMA1_CLK_ENABLE();

  /* DMA interrupt init */
  /* DMA1_Channel6_IRQn interrupt configuration */
  HAL_NVIC_SetPriority(DMA1_Channel6_IRQn, 0, 0);
  HAL_NVIC_EnableIRQ(DMA1_Channel6_IRQn);
  /* DMA1_Channel7_IRQn interrupt configuration */
  HAL_NVIC_SetPriority(DMA1_Channel7_IRQn, 0, 0);
  HAL_NVIC_EnableIRQ(DMA1_Channel7_IRQn);

}

static void MX_GPIO_Init(void)
{
  GPIO_InitTypeDef GPIO_InitStruct = {0};

  /* GPIO Ports Clock Enable */
  __HAL_RCC_GPIOC_CLK_ENABLE();
  __HAL_RCC_GPIOF_CLK_ENABLE();
  __HAL_RCC_GPIOA_CLK_ENABLE();
  __HAL_RCC_GPIOB_CLK_ENABLE();
  __HAL_RCC_GPIOD_CLK_ENABLE();

  /*Configure GPIO pin Output Level */
  HAL_GPIO_WritePin(GPIOA, LED_PIN_Pin|GPIO_PIN_9, GPIO_PIN_RESET);

  /*Configure GPIO pin : B1_Pin */
  GPIO_InitStruct.Pin = B1_Pin;
  GPIO_InitStruct.Mode = GPIO_MODE_IT_FALLING;
  GPIO_InitStruct.Pull = GPIO_NOPULL;
  HAL_GPIO_Init(B1_GPIO_Port, &GPIO_InitStruct);

  /*Configure GPIO pins : LED_PIN_Pin PA9 */
  GPIO_InitStruct.Pin = LED_PIN_Pin|GPIO_PIN_9;
  GPIO_InitStruct.Mode = GPIO_MODE_OUTPUT_PP;
  GPIO_InitStruct.Pull = GPIO_NOPULL;
  GPIO_InitStruct.Speed = GPIO_SPEED_FREQ_LOW;
  HAL_GPIO_Init(GPIOA, &GPIO_InitStruct);

  /*Configure GPIO pin : PC12 */
  GPIO_InitStruct.Pin = GPIO_PIN_12;
  GPIO_InitStruct.Mode = GPIO_MODE_AF_PP;
  GPIO_InitStruct.Pull = GPIO_NOPULL;
  GPIO_InitStruct.Speed = GPIO_SPEED_FREQ_HIGH;
  GPIO_InitStruct.Alternate = GPIO_AF5_UART5;
  HAL_GPIO_Init(GPIOC, &GPIO_InitStruct);

  /*Configure GPIO pin : PD2 */
  GPIO_InitStruct.Pin = GPIO_PIN_2;
  GPIO_InitStruct.Mode = GPIO_MODE_AF_PP;
  GPIO_InitStruct.Pull = GPIO_NOPULL;
  GPIO_InitStruct.Speed = GPIO_SPEED_FREQ_HIGH;
  GPIO_InitStruct.Alternate = GPIO_AF5_UART5;
  HAL_GPIO_Init(GPIOD, &GPIO_InitStruct);

}

/* USER CODE BEGIN 4 */
void SetControlParameters(uint8_t Active, uint8_t MControlMode,
		float MDesiredValueX, float MDesiredValueY, uint8_t EControlMode,
		float EDesiredValueU, float EDesiredValueV, uint8_t Log) {

	YActuator.ControllerActive = Active;

	if (MControlMode != DONT_CHANGE_IT) {

//			if (MControlMode
//					!= YActuator.MC.ControlMode && MControlMode != POSITION_CONTROL) {
//				ReInitMechanicalController(V);
//				YActuator.MC.startPos = YActuator.MC.posSetY;
//				YActuator.MC.velCounter = 0;
//			}
//			if ((MControlMode == YActuator.MC.ControlMode
//					&& MControlMode == VELOCITY_CONTROL
//					&& MDesiredValue != YActuator.MC.DesiredValueY)) {
//				YActuator.MC.startPos = YActuator.MC.posSetY;
//				YActuator.MC.velCounter = 0;
//			}

		YActuator.MC.ControlMode = MControlMode;

//		XActuator.MC.DesiredValue = MDesiredValueX
//				* (float) DesiredTransformation
//				+ MDesiredValueY * (float) DesiredTransformation;
//
//		YActuator.MC.DesiredValue = MDesiredValueX * -1.0f
//				* (float) DesiredTransformation
//				+ MDesiredValueY * (float) DesiredTransformation;

		XActuator.MC.DesiredValue = MDesiredValueX;

		YActuator.MC.DesiredValue = MDesiredValueY;

	}

	if (EControlMode != DONT_CHANGE_IT) {
		if (EControlMode != YActuator.EC.ControlMode) {
			YActuator.EC.Error[1] = 0;
			YActuator.EC.ControlEffort[1] = 0;
			XActuator.EC.Error[1] = 0;
			XActuator.EC.ControlEffort[1] = 0;
		}
		YActuator.EC.ControlMode = EControlMode;
		YActuator.EC.DesiredValue = EDesiredValueV;
		XActuator.EC.DesiredValue = EDesiredValueU;
	}
	ControlLog = Log;

}
void ReInitMechanicalController() {

	YActuator.MC.Error[0] = 0;
	YActuator.MC.Error[1] = 0;
	YActuator.MC.Error[2] = 0;
	YActuator.MC.ControlEffort[0] = 0;
	YActuator.MC.ControlEffort[1] = 0;
	YActuator.MC.ControlEffort[2] = 0;

	// ZPETC Y
	YActuator.MC.ControlEffortZP[0] = 0;
	YActuator.MC.ControlEffortZP[1] = 0;
	YActuator.MC.DesiredValueZP[0] = 0;
	YActuator.MC.DesiredValueZP[1] = 0;
	YActuator.MC.DesiredValueZP[2] = 0;
	YActuator.MC.DesiredValueZP_P1 = 0;

	XActuator.MC.Error[0] = 0;
	XActuator.MC.Error[1] = 0;
	XActuator.MC.Error[2] = 0;
	XActuator.MC.ControlEffort[0] = 0;
	XActuator.MC.ControlEffort[1] = 0;
	XActuator.MC.ControlEffort[2] = 0;

	// ZPETC X
	XActuator.MC.ControlEffortZP[0] = 0;
	XActuator.MC.ControlEffortZP[1] = 0;
	XActuator.MC.DesiredValueZP[0] = 0;
	XActuator.MC.DesiredValueZP[1] = 0;
	XActuator.MC.DesiredValueZP[2] = 0;
	XActuator.MC.DesiredValueZP_P1 = 0;

}
void StartActuators() {

// Linear
	BridgeDriver(V, 0);
	MMeasurement();
	YActuator.MC.Updated = 0;
	HAL_TIM_PWM_Start(&htim1, TIM_CHANNEL_1);
	HAL_TIM_PWM_Start(&htim1, TIM_CHANNEL_2);

	HAL_ADC_Start_IT(&hadc2);

// Rotary
	BridgeDriver(U, 0);
	XActuator.MC.Updated = 0;
	HAL_TIM_PWM_Start(&htim1, TIM_CHANNEL_3);
	HAL_TIM_PWM_Start(&htim1, TIM_CHANNEL_4);

	HAL_ADC_Start_IT(&hadc3);

}
void StopActuators() {

//Linear
	HAL_ADC_Stop_IT(&hadc2);
	HAL_TIM_PWM_Stop(&htim1, TIM_CHANNEL_1);
	HAL_TIM_PWM_Stop(&htim1, TIM_CHANNEL_2);
	YActuator.MM.Counter = 0;
	YActuator.MC.ControlEffort[0] = 0;
	YActuator.MC.ControlEffort[1] = 0;
	YActuator.MC.ControlEffort[2] = 0;
	YActuator.MC.Error[1] = 0;
	YActuator.MC.Error[2] = 0;
	YActuator.EM.Counter = 0;
	YActuator.EC.ControlEffort[1] = 0;
	YActuator.EC.Error[0] = 0;
	YActuator.EC.Error[1] = 0;
	YActuator.MC.posSetY = 0;
	YActuator.MC.startPos = 0;
	// ZPETC Y
	YActuator.MC.ControlEffortZP[0] = 0;
	YActuator.MC.ControlEffortZP[1] = 0;
	YActuator.MC.DesiredValueZP[0] = 0;
	YActuator.MC.DesiredValueZP[1] = 0;
	YActuator.MC.DesiredValueZP[2] = 0;
	YActuator.MC.DesiredValueZP_P1 = 0;
	SetControlParameters(0, MEASUREMENT_ONLY, 0, 0,
	MEASUREMENT_ONLY, 0, 0, 0);
	BridgeDriver(V, 0);

//Rotary
	HAL_ADC_Stop_IT(&hadc3);
	HAL_TIM_PWM_Stop(&htim1, TIM_CHANNEL_3);
	HAL_TIM_PWM_Stop(&htim1, TIM_CHANNEL_4);
	XActuator.MM.Counter = 0;
	XActuator.MC.ControlEffort[1] = 0;
	XActuator.MC.ControlEffort[2] = 0;
	XActuator.MC.Error[0] = 0;
	XActuator.MC.Error[1] = 0;
	XActuator.MC.Error[2] = 0;
	XActuator.EM.Counter = 0;
	XActuator.EC.ControlEffort[1] = 0;
	XActuator.EC.Error[0] = 0;
	XActuator.EC.Error[1] = 0;
	XActuator.MC.posSetY = 0;
	XActuator.MC.startPos = 0;
	// ZPETC X
	XActuator.MC.ControlEffortZP[0] = 0;
	XActuator.MC.ControlEffortZP[1] = 0;
	XActuator.MC.DesiredValueZP[0] = 0;
	XActuator.MC.DesiredValueZP[1] = 0;
	XActuator.MC.DesiredValueZP[2] = 0;
	XActuator.MC.DesiredValueZP_P1 = 0;
//	SetControlParameters(0, MEASUREMENT_ONLY, 0 ,0,
//	MEASUREMENT_ONLY, 0, 0, 0);
	BridgeDriver(U, 0);

	LogCounter = 0;
	PrintCounter = 0;

}
volatile uint8_t ProcessSerialCommand(uint8_t *SerialCommand) {
	uint8_t ActiveCommand;
	if (!strncmp("HOME", (const char*) SerialCommand, 4))
		ActiveCommand = HOME_COMMAND;
	else if (!strncmp("STRT", (const char*) SerialCommand, 4))
		ActiveCommand = START_COMMAND;
	else if (!strncmp("STOP", (const char*) SerialCommand, 4))
		ActiveCommand = STOP_COMMAND;
	else if (!strncmp("MSRM", (const char*) SerialCommand, 4))
		ActiveCommand = MEASUREMENT_COMMAND;
	else if (!strncmp("COFF", (const char*) SerialCommand, 4))
		ActiveCommand = CURRENT_OFFSET_COMMAND;

	else if (!strncmp("LVST", (const char*) SerialCommand, 4))
		ActiveCommand = LINEAR_VOLTAGE_STEP_COMMAND;
	else if (!strncmp("LCST", (const char*) SerialCommand, 4))
		ActiveCommand = LINEAR_CURRENT_STEP_COMMAND;
	else if (!strncmp("LPST", (const char*) SerialCommand, 4))
		ActiveCommand = LINEAR_POSITION_STEP_COMMAND;
	else if (!strncmp("LPRA", (const char*) SerialCommand, 4))
		ActiveCommand = LINEAR_POSITION_RAMP_COMMAND;
	else if (!strncmp("STAR", (const char*) SerialCommand, 4))
		ActiveCommand = STAIR_COMMAND;

	else if (!strncmp("CIRC", (const char*) SerialCommand, 4))
		ActiveCommand = CIRCLE_COMMAND;
	else if (!strncmp("PETL", (const char*) SerialCommand, 4))
		ActiveCommand = PETAL_COMMAND;
	else if (!strncmp("LIS1", (const char*) SerialCommand, 4))
		ActiveCommand = LISSAJOUS12_COMMAND;
	else if (!strncmp("LIS2", (const char*) SerialCommand, 4))
		ActiveCommand = LISSAJOUS23_COMMAND;
	else if (!strncmp("EPIT", (const char*) SerialCommand, 4))
		ActiveCommand = EPITROCHOID_COMMAND;
	else if (!strncmp("SQUR", (const char*) SerialCommand, 4))
		ActiveCommand = SQUARE_COMMAND;
	else if (!strncmp("TRIA", (const char*) SerialCommand, 4))
		ActiveCommand = TRIANGLE_COMMAND;
	else if (!strncmp("SINX", (const char*) SerialCommand, 4))
		ActiveCommand = SINX_COMMAND;
	else if (!strncmp("SINY", (const char*) SerialCommand, 4))
		ActiveCommand = SINY_COMMAND;
	else if (!strncmp("SIST", (const char*) SerialCommand, 4))
		ActiveCommand = SINX_COMMAND;  // Backward-compatible alias for SINX.
	else if (!strncmp("PRNT", (const char*) SerialCommand, 4))
		ActiveCommand = PRINT_COMMAND;
	else if (!strncmp("CURR", (const char*) SerialCommand, 4))
		ActiveCommand = CURRENT_PRINT_COMMAND;

	else
		ActiveCommand = IDLE_COMMAND;
	memset(SerialCommand, '\0', 25);
	return ActiveCommand;
}

void MMeasurement() {

	if (YActuator.MC.Updated == 1)
		LogOverrun++;

	XActuator.MM.Position = ((float) XActuator.MP.EncoderOffset
			- __HAL_TIM_GET_COUNTER(&htim4)) * XActuator.MP.EncoderGain + 8;

	YActuator.MM.Position = -((float) YActuator.MP.EncoderOffset
			- __HAL_TIM_GET_COUNTER(&htim3)) * YActuator.MP.EncoderGain;

//	PosU = XActuator.MM.Position * -1.0f * Transformation
//			+ YActuator.MM.Position * Transformation;
//
//	PosV = XActuator.MM.Position * Transformation
//			+ YActuator.MM.Position * Transformation;

	PosU = XActuator.MM.Position * (float) DesiredTransformation
			+ YActuator.MM.Position * (float) DesiredTransformation;

	PosV = XActuator.MM.Position * -1.0f * (float) DesiredTransformation
			+ YActuator.MM.Position * (float) DesiredTransformation;

}
void EMeasurement() {

	YActuator.EM.Current = -((float) HAL_ADC_GetValue(&hadc2)
			- YActuator.EP.LEMOffset) / 4096.0f * 3.3f * YActuator.EP.LEMGain;

	XActuator.EM.Current = (HAL_ADC_GetValue(&hadc3) - XActuator.EP.LEMOffset)
			/ 4096.0f * 3.3 * XActuator.EP.LEMGain;

}
void LogData() {
	if (LogCounter % 10 == 0) {

		if (YActuator.MC.Updated == 1 && ControlLog == 1) {

//			data[LogCounter / 24 - 1][0] = YActuator.MM.Position;
////			data[LogCounter / 24 - 1][0] = YActuator.MC.posSet;
//
//			for (uint8_t i = 0; i < 24; i++)
//				YActuator.EMLog.Current +=
//						YActuator.EM.CurrentHistory[i];
//			data[LogCounter / 24 - 1][1] = YActuator.EMLog.Current /=
//					(float) 24.000f;

//			data[LogCounter / (SamplingFreq/PrintFreq) - 1][0] = XActuator.MC.posSet;
//			data[LogCounter / (SamplingFreq/PrintFreq) - 1][1] = XyActuator.EM.Current;

		}

		if (XActuator.MC.Updated == 1 && ControlLog == 1) {
//			memcpy(&XActuator.MMLog, &XActuator.MM,
//					sizeof(XActuator.MM));
//			memcpy(&XActuator.EMLog, &XActuator.EM,
//					sizeof(XActuator.EM));
//			memcpy(&XActuator.MCLog, &XActuator.MC,
//					sizeof(XActuator.MC));
//			memcpy(&XActuator.ECLog, &XActuator.EC,
//					sizeof(XActuator.EC));

//			for (uint8_t i = 0; i < 24; i++)
//				XActuator.EMLog.Current +=
//						XActuator.EM.CurrentHistory[i];
//			XActuator.EMLog.Current /= (float) 24.0f;
			//		memcpy(&ControlParametersLog, &ControlParameters,
			//				sizeof(ControlParameters));
			//		for (uint8_t i = 0; i < (EM.Frequency / MM.Frequency); i++)
			//			EMLog.Current += EM.CurrentHistory[i];
			//		EMLog.Current /= (float) (EM.Frequency / MM.Frequency);
//			if (DataLogStatus == LOG_NEW_DATA_READY)
//				SerialOverrun++;

//			data[LogCounter / (SamplingFreq/PrintFreq) - 1][0] = XActuator.MM.Position;
//			data[LogCounter / (SamplingFreq/PrintFreq) - 1][1] = XActuator.EM.Current;

			DataLogStatus = LOG_NEW_DATA_READY;
			XActuator.MC.Updated = 0;

		}
	}

}

// ILC conversion helpers: data arrays use micrometres to reduce SRAM usage.
static int16_t ILC_MmToMicrometres(float valueMm)
{
    const float valueUm = valueMm * 1000.0f;

    // Saturate before conversion so out-of-range values cannot overflow int16_t.
    if (valueUm >= 32767.0f) {
        return (int16_t)32767;
    }
    if (valueUm <= -32768.0f) {
        return (int16_t)(-32767 - 1);
    }

    // Round to the nearest micrometre rather than truncating toward zero.
    if (valueUm >= 0.0f) {
        return (int16_t)(valueUm + 0.5f);
    }
    return (int16_t)(valueUm - 0.5f);
}

static float ILC_MicrometresToMm(int16_t valueUm)
{
    return (float)valueUm * 0.001f;
}

/* Clear the shared correction profile only when switching trajectory type. */
static void ILC_ResetCorrections(void)
{
    for (uint32_t k = 0U; k < ILC_TRIAL_SAMPLES; ++k) {
        ilcCorrectionX_um[k] = 0;
        ilcCorrectionY_um[k] = 0;
    }
}

static float ILC_CalculateRMS(const volatile int16_t *errorUm)
{
    float sum = 0.0f;

    for (uint32_t k = 0U; k < ILC_TRIAL_SAMPLES; ++k) {
        const float e = ILC_MicrometresToMm(errorUm[k]);
        sum += e * e;
    }

    return sqrtf(sum / (float)ILC_TRIAL_SAMPLES);
}

/*
 * RMS over the steady-state evaluation window only.
 * ILC_RMS_START_SAMPLE is 1-based, so sample 1000 corresponds to C index 999.
 * With 5000 trial samples, this evaluates samples 1000 through 5000 inclusive
 * (4001 samples) and excludes the initial transient samples 1 through 999.
 */
static float ILC_CalculateRMS_SteadyState(const volatile int16_t *errorUm)
{
    float sum = 0.0f;
    const uint32_t firstIndex = ILC_RMS_START_SAMPLE - 1U;
    const uint32_t sampleCount = ILC_TRIAL_SAMPLES - firstIndex;

    for (uint32_t k = firstIndex; k < ILC_TRIAL_SAMPLES; ++k) {
        const float e = ILC_MicrometresToMm(errorUm[k]);
        sum += e * e;
    }

    return sqrtf(sum / (float)sampleCount);
}

static float ILC_MaxCorrection(const volatile int16_t *correctionUm)
{
    float peak = 0.0f;

    for (uint32_t k = 0U; k < ILC_TRIAL_SAMPLES; ++k) {
        const float u = fabsf(ILC_MicrometresToMm(correctionUm[k]));
        if (u > peak) {
            peak = u;
        }
    }

    return peak;
}

/* Apply the selected PD-ILC learning law to both axes. */
static void PDILC_Update(void)
{
    PDILC_UpdateAxis(ilcErrorX_um, ilcCorrectionX_um, PDILC_KP_X, PDILC_KD_X);
    PDILC_UpdateAxis(ilcErrorY_um, ilcCorrectionY_um, PDILC_KP_Y, PDILC_KD_Y);
}

/*
 * PD-ILC update for one axis.
 * No beta/learning-scale multiplier is used in this PD update.
 * Forward-backward Q filtering is active; the causal alternative is kept
 * commented below so it can be restored for comparison.
 */
static void PDILC_UpdateAxis(
    volatile int16_t *errorUm,
    volatile int16_t *correctionUm,
    float kp,
    float kd)
{
    const float pi = 3.14159265358979323846f;
    const float sqrt2 = 1.41421356237f;

    const float K = tanf(pi * PDILC_Q_FC_HZ / SamplingFreq);
    const float norm = 1.0f / (1.0f + sqrt2 * K + K * K);

    const float b0 = K * K * norm;
    const float b1 = 2.0f * b0;
    const float b2 = b0;
    const float a1 = 2.0f * (K * K - 1.0f) * norm;
    const float a2 = (1.0f - sqrt2 * K + K * K) * norm;

    /*
     * 1. Calculate the unfiltered PD-ILC update.
     *
     * u_(j+1)[k] = u_j[k]
     *            + Kp * e_j[k+1]
     *            + Kd * (e_j[k+1] - e_j[k])
     *
     * The final sample uses e[k+1] = e[k] to avoid indexing beyond the trial.
     */
    for (uint32_t k = 0U; k < ILC_TRIAL_SAMPLES; ++k) {
        const uint32_t kp1 =
            (k < ILC_TRIAL_SAMPLES - 1U) ? (k + 1U) : k;

        const float e  = ILC_MicrometresToMm(errorUm[k]);
        const float en = ILC_MicrometresToMm(errorUm[kp1]);
        const float delta = kp * en + kd * (en - e);

        float nextU = ILC_MicrometresToMm(correctionUm[k]) + delta;

        // Preserve the existing correction limit before Q filtering.
        if (nextU > ILC_MAX_CORRECTION_MM) {
            nextU = ILC_MAX_CORRECTION_MM;
        } else if (nextU < -ILC_MAX_CORRECTION_MM) {
            nextU = -ILC_MAX_CORRECTION_MM;
        }

        // Store the unfiltered candidate temporarily (1 um resolution).
        correctionUm[k] = ILC_MmToMicrometres(nextU);
    }

    /*
     * 2A. CAUSAL Q-FILTER (ALTERNATIVE; COMMENTED OUT)
     *
     * To use the causal filter, enable this block and disable the active
     * forward-backward block below. Zero initial states match MATLAB
     * filter(b,a,x). The array is filtered in place; no extra trial buffer
     * is required.
     *
     * float x1 = 0.0f;
     * float x2 = 0.0f;
     * float y1 = 0.0f;
     * float y2 = 0.0f;
     *
     * for (uint32_t k = 0U; k < ILC_TRIAL_SAMPLES; ++k) {
     *     const float x = ILC_MicrometresToMm(correctionUm[k]);
     *     const float y = b0*x + b1*x1 + b2*x2 - a1*y1 - a2*y2;
     *     correctionUm[k] = ILC_MmToMicrometres(y);
     *     x2 = x1; x1 = x;
     *     y2 = y1; y1 = y;
     * }
     */

    /*
     * 2B. FORWARD-BACKWARD Q-FILTER (ACTIVE)
     *
     * Filter forward and then backward with the same second-order Butterworth
     * low-pass filter. This reduces the phase delay of the forward pass.
     * This lightweight in-place implementation does not use MATLAB filtfilt()
     * and does not allocate another 5000-sample buffer. The boundary states
     * are initialized to the first/last sample (steady-value initialization).
     */

    // Forward pass: steady-value initialization at the first sample.
    float x1 = ILC_MicrometresToMm(correctionUm[0]);
    float x2 = x1;
    float y1 = x1;
    float y2 = x1;

    for (uint32_t k = 0U; k < ILC_TRIAL_SAMPLES; ++k) {
        const float x = ILC_MicrometresToMm(correctionUm[k]);
        const float y = b0*x + b1*x1 + b2*x2 - a1*y1 - a2*y2;

        correctionUm[k] = ILC_MmToMicrometres(y);

        // Advance input/output histories using the unquantized filter state.
        x2 = x1;
        x1 = x;
        y2 = y1;
        y1 = y;
    }

    // Reverse pass: initialize histories from the final forward-filtered sample.
    x1 = ILC_MicrometresToMm(correctionUm[ILC_TRIAL_SAMPLES - 1U]);
    x2 = x1;
    y1 = x1;
    y2 = x1;

    for (int32_t k = (int32_t)ILC_TRIAL_SAMPLES - 1; k >= 0; --k) {
        const uint32_t index = (uint32_t)k;
        const float x = ILC_MicrometresToMm(correctionUm[index]);
        const float y = b0*x + b1*x1 + b2*x2 - a1*y1 - a2*y2;

        correctionUm[index] = ILC_MmToMicrometres(y);

        // Reverse histories move toward lower sample indices.
        x2 = x1;
        x1 = x;
        y2 = y1;
        y1 = y;
    }

    /*
     * 3. Preserve the existing endpoint constraints.
     */
    correctionUm[0] = 0;
    correctionUm[ILC_TRIAL_SAMPLES - 1U] = 0;

    /*
     * 4. Preserve the existing correction limit after filtering.
     * Filtering can change the magnitude of the candidate correction, so
     * clamp the final profile again before it is used on the next trial.
     */
    for (uint32_t k = 0U; k < ILC_TRIAL_SAMPLES; ++k) {
        float u = ILC_MicrometresToMm(correctionUm[k]);

        if (u > ILC_MAX_CORRECTION_MM) {
            u = ILC_MAX_CORRECTION_MM;
        } else if (u < -ILC_MAX_CORRECTION_MM) {
            u = -ILC_MAX_CORRECTION_MM;
        }

        correctionUm[k] = ILC_MmToMicrometres(u);
    }
}

/* Apply the selected model-inverse learning law to both axes. */
static void ModelInverseILC_Update(void)
{
    /* Identified X-axis closed-loop model coefficients, Fs = 5000 Hz. */
    ModelInverseILC_UpdateAxis(
        ilcErrorX_um, ilcCorrectionX_um,
        0.00447948986620422f, -0.00440141626816451f,
        -2.85654276760025f, 2.71884749040547f, -0.862229040316752f);

    /* Identified Y-axis closed-loop model coefficients, Fs = 5000 Hz. */
    ModelInverseILC_UpdateAxis(
        ilcErrorY_um, ilcCorrectionY_um,
        0.00441711513541465f, -0.00437002549102584f,
        -2.8092450479783f, 2.62331485857184f, -0.814023391722133f);
}

/*
 * Model-inverse ILC update for one axis. Each axis has an independent error
 * profile, correction profile, and identified closed-loop model. ILC_BETA is
 * used by model-inverse ILC only; PD ILC does not use this gain.
 */
static void ModelInverseILC_UpdateAxis(
    volatile int16_t *errorUm,
    volatile int16_t *correctionUm,
    float b1Plant,
    float b2Plant,
    float a1Plant,
    float a2Plant,
    float a3Plant)
{
    const float pi = 3.14159265358979323846f;
    const float sqrt2 = 1.4142135623730951f;
    const float correctionLimit = ILC_MAX_CORRECTION_MM;

    /* Design the second-order Butterworth low-pass Q-filter. */
    const float K = tanf(pi * MODEL_INVERSE_Q_FC_HZ / SamplingFreq);
    const float K2 = K * K;
    const float qDen = 1.0f + sqrt2 * K + K2;

    const float qB0 = K2 / qDen;
    const float qB1 = 2.0f * K2 / qDen;
    const float qB2 = K2 / qDen;
    const float qA1 = 2.0f * (K2 - 1.0f) / qDen;
    const float qA2 = (1.0f - sqrt2 * K + K2) / qDen;

    /*
     * 1. Apply the inverse model to the recorded tracking error.
     *
     * L*e[k] =
     * (e[k+1] + a1*e[k] + a2*e[k-1] + a3*e[k-2]
     *  - b2*L*e[k-1]) / b1
     *
     * Boundary convention matches the standalone MATLAB code:
     * e[k-1] and e[k-2] initially use e[0]. At the last sample, e[k+1]
     * uses e[last]. Update: u_next = u_previous + ILC_BETA*(L*e).
     */
    float eMinus1 = ILC_MicrometresToMm(errorUm[0]);
    float eMinus2 = eMinus1;
    float inversePrevious = 0.0f;

    for (uint32_t k = 0U; k < ILC_TRIAL_SAMPLES; ++k) {
        const float eNow = ILC_MicrometresToMm(errorUm[k]);
        const float eNext = ILC_MicrometresToMm(
            (k < ILC_TRIAL_SAMPLES - 1U) ? errorUm[k + 1U] : errorUm[k]);

        const float inverseCorrection =
            (eNext + a1Plant * eNow + a2Plant * eMinus1
             + a3Plant * eMinus2 - b2Plant * inversePrevious) / b1Plant;

        float nextCorrection =
            ILC_MicrometresToMm(correctionUm[k])
            + ILC_BETA * inverseCorrection;

        // Hardware safeguard before Q-filtering.
        if (nextCorrection > correctionLimit) {
            nextCorrection = correctionLimit;
        } else if (nextCorrection < -correctionLimit) {
            nextCorrection = -correctionLimit;
        }

        correctionUm[k] = ILC_MmToMicrometres(nextCorrection);

        // Update previous-error and inverse-model histories.
        eMinus2 = eMinus1;
        eMinus1 = eNow;
        inversePrevious = inverseCorrection;
    }

    /*
     * Stage 2A: CAUSAL Q-FILTER (ALTERNATIVE; COMMENTED OUT).
     *
     * Enable this block and disable the forward-backward block to return to
     * a causal Q-filter. This applies one forward pass from sample 0 to
     * sample N-1 and therefore introduces the filter's phase delay.
     *
     * The correction array is filtered in place, so no additional 5000-sample
     * buffer is needed. Zero initial filter states match MATLAB filter(b,a,x).
     *
     * float x1 = 0.0f, x2 = 0.0f, y1 = 0.0f, y2 = 0.0f;
     * for (uint32_t k = 0U; k < ILC_TRIAL_SAMPLES; ++k) {
     *     const float x = ILC_MicrometresToMm(correctionUm[k]);
     *     const float y = qB0*x + qB1*x1 + qB2*x2 - qA1*y1 - qA2*y2;
     *     correctionUm[k] = ILC_MmToMicrometres(y);
     *     x2 = x1; x1 = x; y2 = y1; y1 = y;
     * }
     */

    /*
     * Stage 2B: FORWARD-BACKWARD Q-FILTER (ACTIVE).
     *
     * Apply the same second-order Butterworth Q-filter forward and then
     * backward. The reverse pass reduces the phase delay introduced by the
     * forward pass, approximating zero-phase filtering.
     *
     * This lightweight in-place implementation requires no additional
     * 5000-sample buffer and does not call MATLAB filtfilt(). It uses simple
     * steady-value initialization at the beginning and end of the profile,
     * so its boundary handling is not identical to MATLAB filtfilt().
     */

    // Forward pass: steady-value initialization at the first sample.
    float x1 = ILC_MicrometresToMm(correctionUm[0]);
    float x2 = x1;
    float y1 = x1;
    float y2 = x1;

    for (uint32_t k = 0U; k < ILC_TRIAL_SAMPLES; ++k) {
        const float x = ILC_MicrometresToMm(correctionUm[k]);
        const float y = qB0*x + qB1*x1 + qB2*x2 - qA1*y1 - qA2*y2;

        correctionUm[k] = ILC_MmToMicrometres(y);

        x2 = x1;
        x1 = x;
        y2 = y1;
        y1 = y;
    }

    // Reverse pass: steady-value initialization at the last filtered sample.
    x1 = ILC_MicrometresToMm(correctionUm[ILC_TRIAL_SAMPLES - 1U]);
    x2 = x1;
    y1 = x1;
    y2 = x1;

    for (int32_t k = (int32_t)ILC_TRIAL_SAMPLES - 1; k >= 0; --k) {
        const uint32_t index = (uint32_t)k;
        const float x = ILC_MicrometresToMm(correctionUm[index]);
        const float y = qB0*x + qB1*x1 + qB2*x2 - qA1*y1 - qA2*y2;

        correctionUm[index] = ILC_MmToMicrometres(y);

        x2 = x1;
        x1 = x;
        y2 = y1;
        y1 = y;
    }

    /* 3. Preserve endpoint constraints and re-apply the correction limit. */
    correctionUm[0] = 0;
    correctionUm[ILC_TRIAL_SAMPLES - 1U] = 0;

    for (uint32_t k = 0U; k < ILC_TRIAL_SAMPLES; ++k) {
        float u = ILC_MicrometresToMm(correctionUm[k]);

        if (u > correctionLimit) {
            u = correctionLimit;
        } else if (u < -correctionLimit) {
            u = -correctionLimit;
        }

        correctionUm[k] = ILC_MmToMicrometres(u);
    }
}

void HAL_ADC_ConvCpltCallback(ADC_HandleTypeDef *hadc) {

//	HAL_GPIO_TogglePin(GPIOA,GPIO_PIN_9);

	// Calculate the original reference once per sample.
	float xReference = 0.0f;
	float yReference = 0.0f;

	// Generate the selected single-axis sine reference in the ISR.
	if (ActiveCommand == SINX_COMMAND || ActiveCommand == SINY_COMMAND) {

	    if (LogCounter < SINESTEP_DURATION_SAMPLES) {

		    const uint16_t k = (uint16_t)LogCounter;
            const float sineReference =
                R_circle * sinf(freq_circle * ((float)k / SamplingFreq));

            if (ActiveCommand == SINX_COMMAND) {
                xReference = sineReference;
                yReference = 0.0f;
            } else {
                xReference = 0.0f;
                yReference = sineReference;
            }

	        const float commandedX =
	            xReference + ILC_MicrometresToMm(ilcCorrectionX_um[k]);

	        const float commandedY =
	            yReference + ILC_MicrometresToMm(ilcCorrectionY_um[k]);

	        SetControlParameters(
	            1,
	            POSITION_CONTROL,
	            commandedX,
	            commandedY,
	            DONT_CHANGE_IT,
	            0.0f,
	            0.0f,
	            0
	        );

	    } else if (LogCounter < SINESTEP_TOTAL_SAMPLES) {

	        // Return to the origin with feedback still enabled.
	        SetControlParameters(
	            1,
	            POSITION_CONTROL,
	            0.0f,
	            0.0f,
	            DONT_CHANGE_IT,
	            0.0f,
	            0.0f,
	            0
	        );
	    }
	}

    // CIRC reference generation is handled here in the same real-time path.
    if (ActiveCommand == CIRCLE_COMMAND) {
        if (LogCounter < CIRCLE_RAMP_SAMPLES) {
            // Unlearned linear ramp from the origin to the circle start point.
            const float rampFraction =
                (float)LogCounter / (float)CIRCLE_RAMP_SAMPLES;
            xReference = circleStartX_mm * rampFraction;
            yReference = circleStartY_mm * rampFraction;

            SetControlParameters(
                1, POSITION_CONTROL, xReference, yReference,
                DONT_CHANGE_IT, 0.0f, 0.0f, 0);

        } else if (LogCounter < CIRCLE_TRIAL_END_SAMPLE) {
            // The ILC sample index starts AFTER the ramp, so the ramp is never
            // stored in the error profile and never receives learned correction.
            const uint32_t k = LogCounter - CIRCLE_RAMP_SAMPLES;
            const float trialTime = (float)k / SamplingFreq;
            const float rampEndTime = (float)CIRCLE_RAMP_SAMPLES / SamplingFreq;
            const float omegaT = freq_circle * (rampEndTime + trialTime);

            xReference = R_circle * sinf(omegaT);
            yReference = R_circle * cosf(omegaT);

            const float commandedX =
                xReference + ILC_MicrometresToMm(ilcCorrectionX_um[k]);
            const float commandedY =
                yReference + ILC_MicrometresToMm(ilcCorrectionY_um[k]);

            SetControlParameters(
                1, POSITION_CONTROL, commandedX, commandedY,
                DONT_CHANGE_IT, 0.0f, 0.0f, 0);

        } else if (LogCounter < CIRCLE_TOTAL_SAMPLES) {
            // One-second circular segment completes 10 full cycles at 10 Hz.
            // Hold at the same point on the circle, NOT at the origin.
            xReference = circleStartX_mm;
            yReference = circleStartY_mm;

            SetControlParameters(
                1, POSITION_CONTROL, circleStartX_mm, circleStartY_mm,
                DONT_CHANGE_IT, 0.0f, 0.0f, 0);
        }
    }

    // PETAL ILC uses a ramp, repeatable one-second petal segment, then a hold.
    if (ActiveCommand == PETAL_COMMAND) {
        if (LogCounter < PETAL_RAMP_SAMPLES) {
            // The approach ramp is deliberately unlearned.
            const float rampFraction =
                (float)LogCounter / (float)PETAL_RAMP_SAMPLES;
            xReference = petalStartX_mm * rampFraction;
            yReference = petalStartY_mm * rampFraction;

            SetControlParameters(
                1, POSITION_CONTROL, xReference, yReference,
                DONT_CHANGE_IT, 0.0f, 0.0f, 0);

        } else if (LogCounter < PETAL_TRIAL_END_SAMPLE) {
            // Rebase k to zero just after the ramp. Because petal_num=5 is odd,
            // the Cartesian petal shape repeats every 0.25 seconds; this 1-second
            // learning window contains four complete repeats of the same path.
            const uint32_t k = LogCounter - PETAL_RAMP_SAMPLES;
            const float trialTime = (float)k / SamplingFreq;
            const float rampEndTime = (float)PETAL_RAMP_SAMPLES / SamplingFreq;
            const float theta = petal_turn * (rampEndTime + trialTime) * petal_freq;

            xReference = petal_dim * cosf(petal_num * theta) * cosf(theta);
            yReference = petal_dim * cosf(petal_num * theta) * sinf(theta);

            const float commandedX =
                xReference + ILC_MicrometresToMm(ilcCorrectionX_um[k]);
            const float commandedY =
                yReference + ILC_MicrometresToMm(ilcCorrectionY_um[k]);

            SetControlParameters(
                1, POSITION_CONTROL, commandedX, commandedY,
                DONT_CHANGE_IT, 0.0f, 0.0f, 0);

        } else if (LogCounter < PETAL_TOTAL_SAMPLES) {
            // Hold at the same point where the ramp ends and PETAL learning starts.
            xReference = petalStartX_mm;
            yReference = petalStartY_mm;

            SetControlParameters(
                1, POSITION_CONTROL, petalStartX_mm, petalStartY_mm,
                DONT_CHANGE_IT, 0.0f, 0.0f, 0);
        }
    }

    // Lissajous ILC: serial command LIS1 selects 1:2; LIS2 selects 2:3.
    if (ActiveCommand == LISSAJOUS12_COMMAND || ActiveCommand == LISSAJOUS23_COMMAND) {
        const uint8_t isRatio12 = (ActiveCommand == LISSAJOUS12_COMMAND);
        const float lissFx_Hz = isRatio12 ? LISSAJOUS12_FX_HZ : LISSAJOUS23_FX_HZ;
        const float lissFy_Hz = isRatio12 ? LISSAJOUS12_FY_HZ : LISSAJOUS23_FY_HZ;

        if (LogCounter < LISSAJOUS_RAMP_SAMPLES) {
            // Unlearned ramp from the origin to the path point at t = 0.25 s.
            const float rampFraction =
                (float)LogCounter / (float)LISSAJOUS_RAMP_SAMPLES;
            xReference = lissajousStartX_mm * rampFraction;
            yReference = lissajousStartY_mm * rampFraction;

            SetControlParameters(
                1, POSITION_CONTROL, xReference, yReference,
                DONT_CHANGE_IT, 0.0f, 0.0f, 0);

        } else if (LogCounter < LISSAJOUS_TRIAL_END_SAMPLE) {
            // Learning begins at t = ramp duration and repeats exactly every second.
            const uint32_t k = LogCounter - LISSAJOUS_RAMP_SAMPLES;
            const float trialTime = (float)k / SamplingFreq;
            const float trajectoryTime =
                ((float)LISSAJOUS_RAMP_SAMPLES / SamplingFreq) + trialTime;

            xReference = LISSAJOUS_A_X_MM *
                sinf(2.0f * (float)M_PI * lissFx_Hz * trajectoryTime);
            yReference = LISSAJOUS_A_Y_MM *
                sinf(2.0f * (float)M_PI * lissFy_Hz * trajectoryTime + LISSAJOUS_PHASE_Y_RAD);

            const float commandedX =
                xReference + ILC_MicrometresToMm(ilcCorrectionX_um[k]);
            const float commandedY =
                yReference + ILC_MicrometresToMm(ilcCorrectionY_um[k]);

            SetControlParameters(
                1, POSITION_CONTROL, commandedX, commandedY,
                DONT_CHANGE_IT, 0.0f, 0.0f, 0);

        } else if (LogCounter < LISSAJOUS_TOTAL_SAMPLES) {
            // Keep feedback enabled and hold at the same point that starts the path.
            xReference = lissajousStartX_mm;
            yReference = lissajousStartY_mm;

            SetControlParameters(
                1, POSITION_CONTROL, lissajousStartX_mm, lissajousStartY_mm,
                DONT_CHANGE_IT, 0.0f, 0.0f, 0);
        }
    }

	if (YActuator.ControllerActive) {

		switch (YActuator.MC.ControlMode) {

		case POSITION_CONTROL:

			MMeasurement();

			// Record both 1-second Cartesian tracking-error profiles.
			// LogCounter is the sample index at 5 kHz. Store error in micrometres.
			if ((ActiveCommand == SINX_COMMAND || ActiveCommand == SINY_COMMAND) &&
			    LogCounter < ILC_TRIAL_SAMPLES) {

			    const uint32_t k = LogCounter;

			    // Tracking error = original reference - measured position.
			    ilcErrorX_um[k] = ILC_MmToMicrometres(
			        xReference - XActuator.MM.Position);
			    ilcErrorY_um[k] = ILC_MmToMicrometres(
			        yReference - YActuator.MM.Position);

            } else if (ActiveCommand == CIRCLE_COMMAND &&
                       LogCounter >= CIRCLE_RAMP_SAMPLES &&
                       LogCounter < CIRCLE_TRIAL_END_SAMPLE) {

                const uint32_t k = LogCounter - CIRCLE_RAMP_SAMPLES;

                // Store only circular-segment errors. The approach ramp and
                // the hold at the circle start point are not part of ILC.
                ilcErrorX_um[k] = ILC_MmToMicrometres(
                    xReference - XActuator.MM.Position);
                ilcErrorY_um[k] = ILC_MmToMicrometres(
                    yReference - YActuator.MM.Position);

            } else if (ActiveCommand == PETAL_COMMAND &&
                       LogCounter >= PETAL_RAMP_SAMPLES &&
                       LogCounter < PETAL_TRIAL_END_SAMPLE) {

                const uint32_t k = LogCounter - PETAL_RAMP_SAMPLES;

                // Store only the repeatable PETAL segment, excluding ramp and hold.
                ilcErrorX_um[k] = ILC_MmToMicrometres(
                    xReference - XActuator.MM.Position);
                ilcErrorY_um[k] = ILC_MmToMicrometres(
                    yReference - YActuator.MM.Position);

            } else if ((ActiveCommand == LISSAJOUS12_COMMAND ||
                        ActiveCommand == LISSAJOUS23_COMMAND) &&
                       LogCounter >= LISSAJOUS_RAMP_SAMPLES &&
                       LogCounter < LISSAJOUS_TRIAL_END_SAMPLE) {

                const uint32_t k = LogCounter - LISSAJOUS_RAMP_SAMPLES;
                ilcErrorX_um[k] = ILC_MmToMicrometres(
                    xReference - XActuator.MM.Position);
                ilcErrorY_um[k] = ILC_MmToMicrometres(
                    yReference - YActuator.MM.Position);
			}

//			 //ZPETC

//
//			YActuator.MC.DesiredValueZP_P1 = (float)YActuator.MC.DesiredValue;
//			XActuator.MC.DesiredValueZP_P1 = (float)XActuator.MC.DesiredValue;
//
//
//			YActuator.MC.ControlEffortZP[0] =
//					0.9893392762142f * YActuator.MC.ControlEffortZP[1]
//									+ 226.3921064638779f * YActuator.MC.DesiredValueZP_P1
//										 - 635.9909039850245f * YActuator.MC.DesiredValueZP[0]
//											+ 593.8977767500685f * YActuator.MC.DesiredValueZP[1]
//											 - 184.2884703628441f * YActuator.MC.DesiredValueZP[2];
//
//			XActuator.MC.ControlEffortZP[0] =
//					0.9825708729405f * XActuator.MC.ControlEffortZP[1]
//									+ 223.2397058300233f * XActuator.MC.DesiredValueZP_P1
//										 - 637.6937671299596f * XActuator.MC.DesiredValueZP[0]
//											+ 606.9547139548133f * XActuator.MC.DesiredValueZP[1]
//											 - 192.4837573184151f * XActuator.MC.DesiredValueZP[2];
//
//			YActuator.MC.posSetY = YActuator.MC.ControlEffortZP[0];
//			XActuator.MC.posSetY = XActuator.MC.ControlEffortZP[0];
//
//
//			YActuator.MC.ControlEffortZP[1] = YActuator.MC.ControlEffortZP[0];
//			XActuator.MC.ControlEffortZP[1] = XActuator.MC.ControlEffortZP[0];
//
//			YActuator.MC.DesiredValueZP[2] = YActuator.MC.DesiredValueZP[1];
//			YActuator.MC.DesiredValueZP[1] = YActuator.MC.DesiredValueZP[0];
//			YActuator.MC.DesiredValueZP[0] = YActuator.MC.DesiredValueZP_P1;
//
//			XActuator.MC.DesiredValueZP[2] = XActuator.MC.DesiredValueZP[1];
//			XActuator.MC.DesiredValueZP[1] = XActuator.MC.DesiredValueZP[0];
//			XActuator.MC.DesiredValueZP[0] = XActuator.MC.DesiredValueZP_P1;

////
						YActuator.MC.posSetY = YActuator.MC.DesiredValue;
						XActuator.MC.posSetY = XActuator.MC.DesiredValue;

			// X-Y to U-V Transform
			float targetU = XActuator.MC.posSetY
					* (float) DesiredTransformation
					+ YActuator.MC.posSetY * (float) DesiredTransformation;

			float targetV = XActuator.MC.posSetY * -1.0f
					* (float) DesiredTransformation
					+ YActuator.MC.posSetY * (float) DesiredTransformation;

//
//			YActuator.MC.posSetY = YActuator.MC.DesiredValue;
//			XActuator.MC.posSetY = XActuator.MC.DesiredValue;

			YActuator.MC.Error[0] = targetV - PosV;
			XActuator.MC.Error[0] = targetU - PosU;

//// Controller#2 for tracking
//			YActuator.MC.ControlEffort[0] =
//					1.485726401317451f * YActuator.MC.ControlEffort[1]
//							- 0.485746749177129f * YActuator.MC.ControlEffort[2]
//							+ 300.0f
//									* (YActuator.MC.Error[0]
//											- 1.997800000000000f
//													* YActuator.MC.Error[1]
//											+ 0.997801050000000f
//													* YActuator.MC.Error[2]);
//
//			XActuator.MC.ControlEffort[0] =
//					1.485726401317451f * XActuator.MC.ControlEffort[1]
//							- 0.485746749177129f * XActuator.MC.ControlEffort[2]
//							+ 300.0f
//									* (XActuator.MC.Error[0]
//											- 1.997800000000000f
//													* XActuator.MC.Error[1]
//											+ 0.997801050000000f
//													* XActuator.MC.Error[2]);
//

			YActuator.MC.ControlEffort[0] =
					0.751318635846056f * YActuator.MC.ControlEffort[1]
							+ 0.248444252947579f * YActuator.MC.ControlEffort[2]
							+ 152.365f
									* (1.0f * YActuator.MC.Error[0]
										  - 1.989464924548591f
													* YActuator.MC.Error[1]
											+ 0.989489015756025f
													* YActuator.MC.Error[2]);

			XActuator.MC.ControlEffort[0] =
					0.751318635846056f * XActuator.MC.ControlEffort[1]
							+ 0.248444252947579f * XActuator.MC.ControlEffort[2]
							+ 152.365f
									* (1.0f * XActuator.MC.Error[0]
										   - 1.989464924548591f
													* XActuator.MC.Error[1]
											+ 0.989489015756025f
													* XActuator.MC.Error[2]);

//			YActuator.MC.ControlEffort[0] =
//					1.958150112703506f * YActuator.MC.ControlEffort[1]
//							- 0.958154287483996f * YActuator.MC.ControlEffort[2]
//							+ 2.393f
//									* (1.0f * YActuator.MC.Error[0]
//										  - 1.989654379783368f
//													* YActuator.MC.Error[1]
//											+ 0.989663721232611f
//													* YActuator.MC.Error[2]);
//
//			XActuator.MC.ControlEffort[0] =
//					1.958150112703506f * XActuator.MC.ControlEffort[1]
//							- 0.958154287483996f * XActuator.MC.ControlEffort[2]
//							+ 2.393f
//									* (1.0f * XActuator.MC.Error[0]
//										  - 1.989654379783368f
//													* XActuator.MC.Error[1]
//											+ 0.989663721232611f
//													* XActuator.MC.Error[2]);

			YActuator.MC.ControlEffort[2] = YActuator.MC.ControlEffort[1];
			YActuator.MC.ControlEffort[1] = YActuator.MC.ControlEffort[0];
			XActuator.MC.ControlEffort[2] = XActuator.MC.ControlEffort[1];
			XActuator.MC.ControlEffort[1] = XActuator.MC.ControlEffort[0];

			YActuator.MC.Error[2] = YActuator.MC.Error[1];
			YActuator.MC.Error[1] = YActuator.MC.Error[0];
			XActuator.MC.Error[2] = XActuator.MC.Error[1];
			XActuator.MC.Error[1] = XActuator.MC.Error[0];

			SetControlParameters(1, DONT_CHANGE_IT, 0, 0,
			CURRENT_CONTROL, XActuator.MC.ControlEffort[0],
					YActuator.MC.ControlEffort[0], 0);

			YActuator.MM.Counter++;
			YActuator.MC.Updated = 1;

			break;

		case MEASUREMENT_ONLY:

			MMeasurement();
			YActuator.MM.Counter++;
			YActuator.MC.Updated = 1;
			break;

		}

		switch (YActuator.EC.ControlMode) {

		case VOLTAGE_CONTROL:
			EMeasurement();
			BridgeDriver(V, YActuator.EC.DesiredValue);
			BridgeDriver(U, XActuator.EC.DesiredValue);
			YActuator.EM.Counter++;
			break;

		case CURRENT_CONTROL:

			EMeasurement();

			YActuator.EC.Error[0] = YActuator.EC.DesiredValue
					- YActuator.EM.Current;
			XActuator.EC.Error[0] = XActuator.EC.DesiredValue
					- XActuator.EM.Current;

//			XActuator.EC.ControlEffort[0] = 1.0f * XActuator.EC.ControlEffort[1]
//					+ 2.00f
//							* (XActuator.EC.Error[0]
//									- 0.8569f * XActuator.EC.Error[1]);

			YActuator.EC.ControlEffort[0] = 1.0f * YActuator.EC.ControlEffort[1]
					+ 2.54378f
							* (YActuator.EC.Error[0]
									- 0.459953297848084f * YActuator.EC.Error[1]);

			XActuator.EC.ControlEffort[0] = 1.0f * XActuator.EC.ControlEffort[1]
					+ 2.54378f
							* (XActuator.EC.Error[0]
									- 0.459953297848084f * XActuator.EC.Error[1]);

//			YActuator.EC.ControlEffort[0] = 1.0f * YActuator.EC.ControlEffort[1]
//					+ 4.0f
//							* (YActuator.EC.Error[0]
//									- 0.807938892613398f * YActuator.EC.Error[1]);
//
//
//			XActuator.EC.ControlEffort[0] = 1.0f * XActuator.EC.ControlEffort[1]
//					+ 4.0f
//							* (XActuator.EC.Error[0]
//									- 0.807938892613398f * XActuator.EC.Error[1]);

			YActuator.EC.ControlEffort[1] = BridgeDriver(V,
					YActuator.EC.ControlEffort[0]);
			XActuator.EC.ControlEffort[1] = BridgeDriver(U,
					XActuator.EC.ControlEffort[0]);

			YActuator.EC.Error[1] = YActuator.EC.Error[0];
			XActuator.EC.Error[1] = XActuator.EC.Error[0];
			YActuator.EM.Counter++;

			break;

		case MEASUREMENT_ONLY:

			EMeasurement();
//			LogData();
			YActuator.EM.Counter++;
			break;
		}

		// Temporary current logging during the ILC segment.
		// This is after EMeasurement() for the active electrical control mode.
		// Store every 10th trial sample in mA; CIRC's ramp is excluded.
        uint32_t currentLogIndex = 0U;
        uint32_t currentTrialIndex = 0U;
        uint8_t saveCurrentSample = 0U;

        if ((ActiveCommand == SINX_COMMAND || ActiveCommand == SINY_COMMAND) &&
            LogCounter < ILC_TRIAL_SAMPLES) {
            currentTrialIndex = LogCounter;
            if ((currentTrialIndex % CURRENT_LOG_DECIMATION) == 0U) {
                currentLogIndex = currentTrialIndex / CURRENT_LOG_DECIMATION;
                saveCurrentSample = 1U;
            }
        } else if (ActiveCommand == CIRCLE_COMMAND &&
                   LogCounter >= CIRCLE_RAMP_SAMPLES &&
                   LogCounter < CIRCLE_TRIAL_END_SAMPLE) {
            currentTrialIndex = LogCounter - CIRCLE_RAMP_SAMPLES;
            if ((currentTrialIndex % CURRENT_LOG_DECIMATION) == 0U) {
                currentLogIndex = currentTrialIndex / CURRENT_LOG_DECIMATION;
                saveCurrentSample = 1U;
            }
        } else if (ActiveCommand == PETAL_COMMAND &&
                   LogCounter >= PETAL_RAMP_SAMPLES &&
                   LogCounter < PETAL_TRIAL_END_SAMPLE) {
            currentTrialIndex = LogCounter - PETAL_RAMP_SAMPLES;
            if ((currentTrialIndex % CURRENT_LOG_DECIMATION) == 0U) {
                currentLogIndex = currentTrialIndex / CURRENT_LOG_DECIMATION;
                saveCurrentSample = 1U;
            }
        } else if ((ActiveCommand == LISSAJOUS12_COMMAND ||
                    ActiveCommand == LISSAJOUS23_COMMAND) &&
                   LogCounter >= LISSAJOUS_RAMP_SAMPLES &&
                   LogCounter < LISSAJOUS_TRIAL_END_SAMPLE) {
            currentTrialIndex = LogCounter - LISSAJOUS_RAMP_SAMPLES;
            if ((currentTrialIndex % CURRENT_LOG_DECIMATION) == 0U) {
                currentLogIndex = currentTrialIndex / CURRENT_LOG_DECIMATION;
                saveCurrentSample = 1U;
            }
        }

        if (saveCurrentSample && currentLogIndex < CURRENT_LOG_SAMPLES) {
            currentLogX_mA[currentLogIndex] =
                (int16_t)(XActuator.EM.Current * 1000.0f);
            currentLogY_mA[currentLogIndex] =
                (int16_t)(YActuator.EM.Current * 1000.0f);
        }
	}

//	if (LogCounter % 5 == 0 && STPOS == 1) {
//		//&& (LogCounter > 1*SamplingFreq)
//
//		CURRENTLOG_V[PrintCounter] = YActuator.EM.Current;
//		CURRENTLOG_U[PrintCounter] = XActuator.EM.Current;
////		CURRENTLOG_U[PrintCounter] = YActuator.MC.DesiredValueZP[0];
//		PosLog_U[PrintCounter] = XActuator.MC.posSetY;
//	    PosLog_V[PrintCounter] = YActuator.MC.posSetY;
////		PosLog_X[PrintCounter] = YActuator.MC.DesiredValueZP_P1;
//		PosLog_X[PrintCounter] = XActuator.MM.Position;
//		PosLog_Y[PrintCounter] = YActuator.MM.Position;
//
////		LogC[PrintCounter] = LogCounter;
//
////		EC_ConEffX_LOG[PrintCounter] = XActuator.EC.ControlEffort[0];
////		EC_ConEffY_LOG[PrintCounter] = YActuator.EC.ControlEffort[0];
////		MC_ErrX_LOG[PrintCounter] = XActuator.MC.Error[0];
////		MC_ErrY_LOG[PrintCounter] = YActuator.MC.Error[0];
//
////		EC_ErrX_LOG[PrintCounter] = XActuator.EC.Error[0];
////		EC_ErrY_LOG[PrintCounter] = YActuator.EC.Error[0];
//
//		PrintCounter++;
//	}
//
//	if (PrintCounter >= PrintNumbers) {
//		STPOS = 0;
//	}

	LogCounter++;
	HAL_GPIO_TogglePin(GPIOA,GPIO_PIN_9);

}
void HAL_UARTEx_RxEventCallback(UART_HandleTypeDef *huart, uint16_t Size) {
	ActiveCommand = ProcessSerialCommand(UARTRXBuffer);
	HAL_UARTEx_ReceiveToIdle_IT(&huart2, UARTRXBuffer,
	UART_RX_BUFFER_SIZE);
}

volatile float BridgeDriver(uint8_t Axis, float ControlEffort) {

	ControlEffort *= PWMARR / BusVoltage;
	if (ControlEffort >= 0) {
		ControlEffort = (ControlEffort > PWMARR) ?
		PWMARR :
													ControlEffort;
		if (Axis == V) {
			__HAL_TIM_SET_COMPARE(&htim1, TIM_CHANNEL_1, 0);
			__HAL_TIM_SET_COMPARE(&htim1, TIM_CHANNEL_2, ControlEffort);
		} else if (Axis == U) {
			__HAL_TIM_SET_COMPARE(&htim1, TIM_CHANNEL_4, 0);
			__HAL_TIM_SET_COMPARE(&htim1, TIM_CHANNEL_3, ControlEffort);
		}
		return ControlEffort * BusVoltage / PWMARR;
	} else {
		ControlEffort = (-ControlEffort > PWMARR) ?
		PWMARR :
													-ControlEffort;
		if (Axis == V) {
			__HAL_TIM_SET_COMPARE(&htim1, TIM_CHANNEL_2, 0);
			__HAL_TIM_SET_COMPARE(&htim1, TIM_CHANNEL_1, ControlEffort);
		} else if (Axis == U) {
			__HAL_TIM_SET_COMPARE(&htim1, TIM_CHANNEL_3, 0);
			__HAL_TIM_SET_COMPARE(&htim1, TIM_CHANNEL_4, ControlEffort);
		}
		return -ControlEffort * BusVoltage / PWMARR;
	}
}

/* USER CODE END 4 */

void Error_Handler(void)
{
	__disable_irq();
	while (1) {
	}
}
